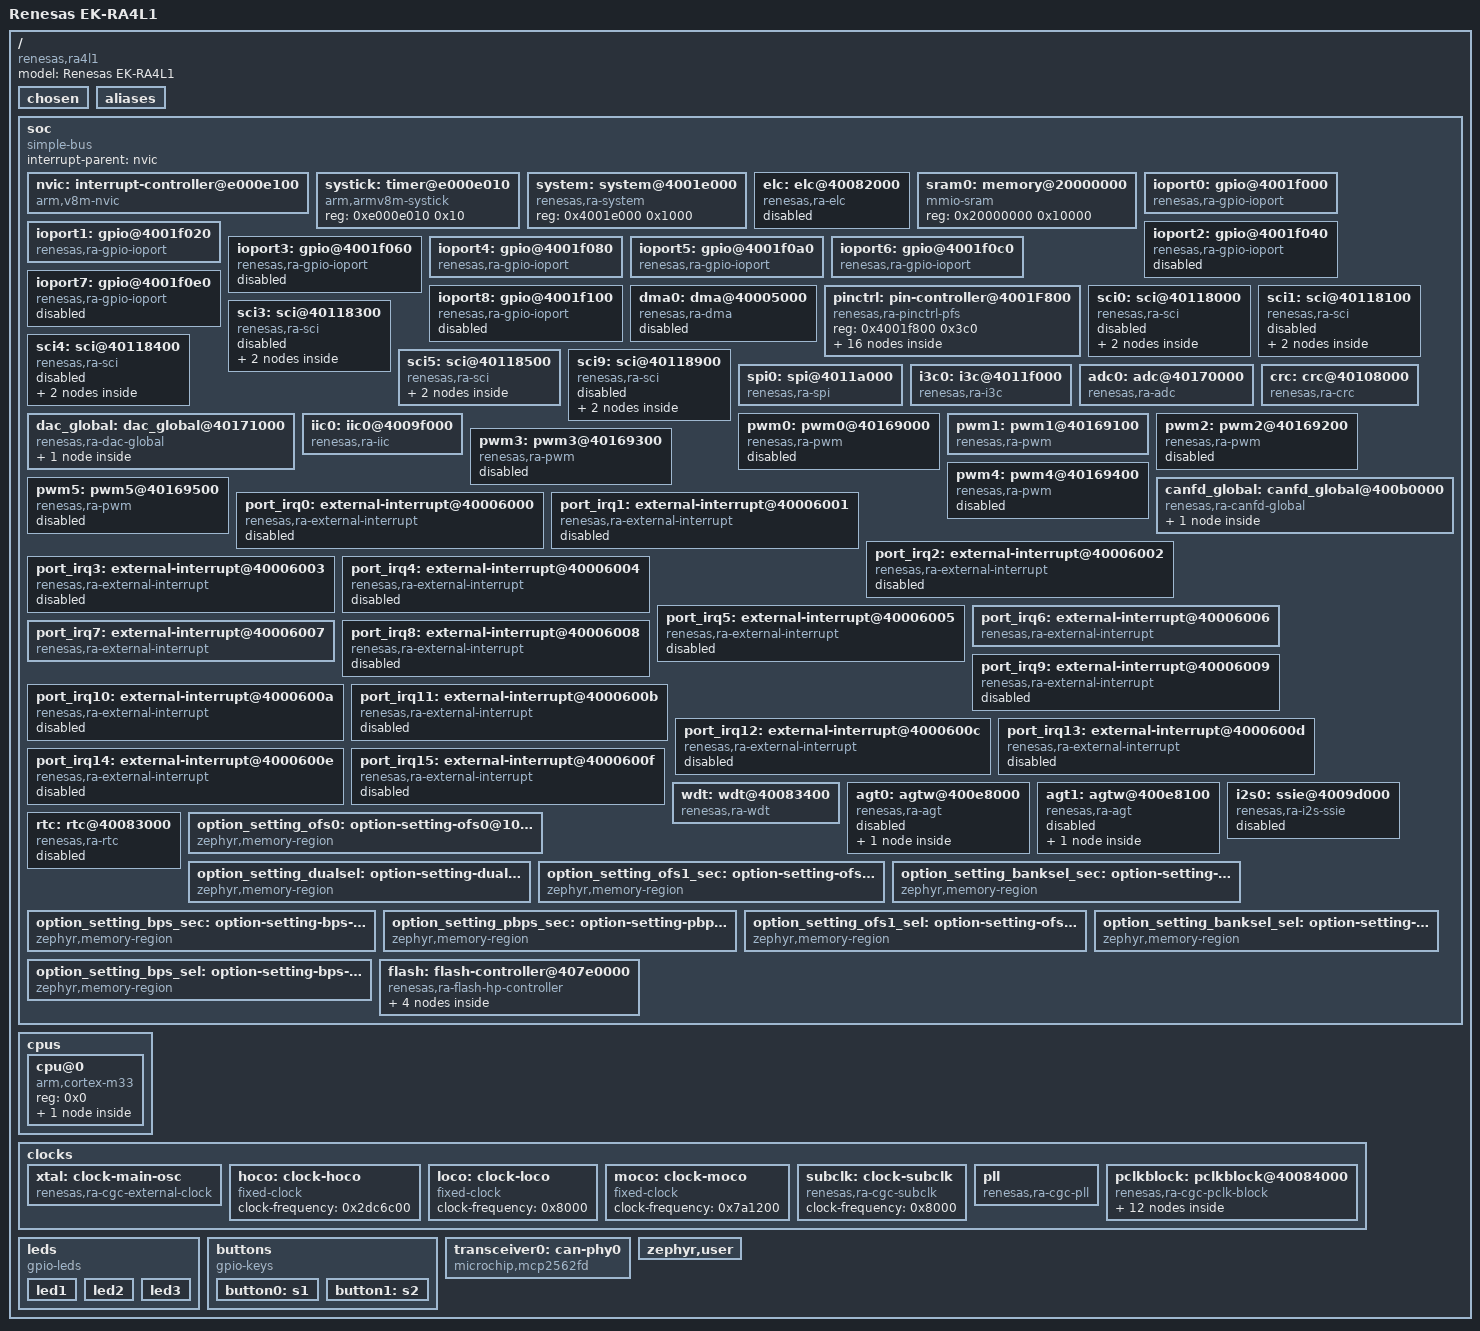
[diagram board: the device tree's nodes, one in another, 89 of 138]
/dts-v1/;

/* node '/' defined in zephyr/dts/common/skeleton.dtsi:9 */
/ {
	#address-cells = < 0x1 >;     /* in zephyr/dts/common/skeleton.dtsi:10 */
	#size-cells = < 0x1 >;        /* in zephyr/dts/common/skeleton.dtsi:11 */
	model = "Renesas EK-RA4L1";   /* in zephyr/boards/renesas/ek_ra4l1/ek_ra4l1.dts:15 */
	compatible = "renesas,ra4l1",
	             "renesas,ra";    /* in zephyr/boards/renesas/ek_ra4l1/ek_ra4l1.dts:16 */

	/* node '/chosen' defined in zephyr/dts/common/skeleton.dtsi:13 */
	chosen {
		zephyr,sram = &sram0;              /* in zephyr/boards/renesas/ek_ra4l1/ek_ra4l1.dts:19 */
		zephyr,flash-controller = &flash1; /* in zephyr/boards/renesas/ek_ra4l1/ek_ra4l1.dts:20 */
		zephyr,flash = &flash0;            /* in zephyr/boards/renesas/ek_ra4l1/ek_ra4l1.dts:21 */
		zephyr,console = &uart5;           /* in zephyr/boards/renesas/ek_ra4l1/ek_ra4l1.dts:22 */
		zephyr,shell-uart = &uart5;        /* in zephyr/boards/renesas/ek_ra4l1/ek_ra4l1.dts:23 */
		zephyr,canbus = &canfd0;           /* in zephyr/boards/renesas/ek_ra4l1/ek_ra4l1.dts:24 */
		zephyr,crc = &crc;                 /* in zephyr/boards/renesas/ek_ra4l1/ek_ra4l1.dts:25 */
	};

	/* node '/aliases' defined in zephyr/dts/common/skeleton.dtsi:15 */
	aliases {
		led0 = &led1;     /* in zephyr/boards/renesas/ek_ra4l1/ek_ra4l1.dts:64 */
		sw0 = &button0;   /* in zephyr/boards/renesas/ek_ra4l1/ek_ra4l1.dts:65 */
		sw1 = &button1;   /* in zephyr/boards/renesas/ek_ra4l1/ek_ra4l1.dts:66 */
		watchdog0 = &wdt; /* in zephyr/boards/renesas/ek_ra4l1/ek_ra4l1.dts:67 */
	};

	/* node '/soc' defined in zephyr/dts/arm/armv8-m.dtsi:6 */
	soc {
		#address-cells = < 0x1 >;     /* in zephyr/dts/arm/armv8-m.dtsi:7 */
		#size-cells = < 0x1 >;        /* in zephyr/dts/arm/armv8-m.dtsi:8 */
		compatible = "simple-bus";    /* in zephyr/dts/arm/armv8-m.dtsi:9 */
		ranges;                       /* in zephyr/dts/arm/armv8-m.dtsi:11 */
		interrupt-parent = < &nvic >; /* in zephyr/dts/arm/renesas/ra/ra4/r7fa4l1bx.dtsi:35 */

		/* node '/soc/interrupt-controller@e000e100' defined in zephyr/dts/arm/armv8-m.dtsi:13 */
		nvic: interrupt-controller@e000e100 {
			#address-cells = < 0x1 >;            /* in zephyr/dts/arm/armv8-m.dtsi:14 */
			compatible = "arm,v8m-nvic";         /* in zephyr/dts/arm/armv8-m.dtsi:15 */
			reg = < 0xe000e100 0xc00 >;          /* in zephyr/dts/arm/armv8-m.dtsi:16 */
			interrupt-controller;                /* in zephyr/dts/arm/armv8-m.dtsi:17 */
			#interrupt-cells = < 0x2 >;          /* in zephyr/dts/arm/armv8-m.dtsi:18 */
			arm,num-irq-priority-bits = < 0x4 >; /* in zephyr/dts/arm/renesas/ra/ra4/r7fa4l1bx.dtsi:839 */
			phandle = < 0x1 >;                   /* in zephyr/dts/arm/renesas/ra/ra4/r7fa4l1bx.dtsi:35 */
		};

		/* node '/soc/timer@e000e010' defined in zephyr/dts/arm/armv8-m.dtsi:21 */
		systick: timer@e000e010 {
			compatible = "arm,armv8m-systick"; /* in zephyr/dts/arm/armv8-m.dtsi:22 */
			reg = < 0xe000e010 0x10 >;         /* in zephyr/dts/arm/armv8-m.dtsi:23 */
		};

		/* node '/soc/system@4001e000' defined in zephyr/dts/arm/renesas/ra/ra4/r7fa4l1bx.dtsi:37 */
		system: system@4001e000 {
			compatible = "renesas,ra-system"; /* in zephyr/dts/arm/renesas/ra/ra4/r7fa4l1bx.dtsi:38 */
			reg = < 0x4001e000 0x1000 >;      /* in zephyr/dts/arm/renesas/ra/ra4/r7fa4l1bx.dtsi:39 */
			status = "okay";                  /* in zephyr/dts/arm/renesas/ra/ra4/r7fa4l1bx.dtsi:40 */
		};

		/* node '/soc/elc@40082000' defined in zephyr/dts/arm/renesas/ra/ra4/r7fa4l1bx.dtsi:43 */
		elc: elc@40082000 {
			compatible = "renesas,ra-elc"; /* in zephyr/dts/arm/renesas/ra/ra4/r7fa4l1bx.dtsi:44 */
			reg = < 0x40082000 0x70 >;     /* in zephyr/dts/arm/renesas/ra/ra4/r7fa4l1bx.dtsi:45 */
			#renesas-elc-cells = < 0x2 >;  /* in zephyr/dts/arm/renesas/ra/ra4/r7fa4l1bx.dtsi:46 */
			clocks = < &pclkb 0x2 0xe >;   /* in zephyr/dts/arm/renesas/ra/ra4/r7fa4l1bx.dtsi:47 */
			status = "disabled";           /* in zephyr/dts/arm/renesas/ra/ra4/r7fa4l1bx.dtsi:48 */
		};

		/* node '/soc/memory@20000000' defined in zephyr/dts/arm/renesas/ra/ra4/r7fa4l1bx.dtsi:51 */
		sram0: memory@20000000 {
			compatible = "mmio-sram";     /* in zephyr/dts/arm/renesas/ra/ra4/r7fa4l1bx.dtsi:52 */
			reg = < 0x20000000 0x10000 >; /* in zephyr/dts/arm/renesas/ra/ra4/r7fa4l1bx.dtsi:53 */
		};

		/* node '/soc/gpio@4001f000' defined in zephyr/dts/arm/renesas/ra/ra4/r7fa4l1bx.dtsi:56 */
		ioport0: gpio@4001f000 {
			compatible = "renesas,ra-gpio-ioport";                                               /* in zephyr/dts/arm/renesas/ra/ra4/r7fa4l1bx.dtsi:57 */
			reg = < 0x4001f000 0x20 >;                                                           /* in zephyr/dts/arm/renesas/ra/ra4/r7fa4l1bx.dtsi:58 */
			port = < 0x0 >;                                                                      /* in zephyr/dts/arm/renesas/ra/ra4/r7fa4l1bx.dtsi:59 */
			gpio-controller;                                                                     /* in zephyr/dts/arm/renesas/ra/ra4/r7fa4l1bx.dtsi:60 */
			#gpio-cells = < 0x2 >;                                                               /* in zephyr/dts/arm/renesas/ra/ra4/r7fa4l1bx.dtsi:61 */
			ngpios = < 0x10 >;                                                                   /* in zephyr/dts/arm/renesas/ra/ra4/r7fa4l1bx.dtsi:62 */
			port-irqs = < &port_irq6 &port_irq7 &port_irq8 &port_irq9 &port_irq10 &port_irq11 >; /* in zephyr/dts/arm/renesas/ra/ra4/r7fa4l1bx.dtsi:843 */
			port-irq-names = "port-irq6",
			                 "port-irq7",
			                 "port-irq8",
			                 "port-irq9",
			                 "port-irq10",
			                 "port-irq11";                                                       /* in zephyr/dts/arm/renesas/ra/ra4/r7fa4l1bx.dtsi:845 */
			port-irq6-pins = < 0x0 >;                                                            /* in zephyr/dts/arm/renesas/ra/ra4/r7fa4l1bx.dtsi:851 */
			port-irq7-pins = < 0x1 >;                                                            /* in zephyr/dts/arm/renesas/ra/ra4/r7fa4l1bx.dtsi:852 */
			port-irq8-pins = < 0x2 >;                                                            /* in zephyr/dts/arm/renesas/ra/ra4/r7fa4l1bx.dtsi:853 */
			port-irq9-pins = < 0x4 >;                                                            /* in zephyr/dts/arm/renesas/ra/ra4/r7fa4l1bx.dtsi:854 */
			port-irq10-pins = < 0xa >;                                                           /* in zephyr/dts/arm/renesas/ra/ra4/r7fa4l1bx.dtsi:855 */
			port-irq11-pins = < 0xb >;                                                           /* in zephyr/dts/arm/renesas/ra/ra4/r7fa4l1bx.dtsi:856 */
			status = "okay";                                                                     /* in zephyr/boards/renesas/ek_ra4l1/ek_ra4l1.dts:125 */
			phandle = < 0x26 >;                                                                  /* in zephyr/boards/renesas/ek_ra4l1/ek_ra4l1.dts:51 */
		};

		/* node '/soc/gpio@4001f020' defined in zephyr/dts/arm/renesas/ra/ra4/r7fa4l1bx.dtsi:66 */
		ioport1: gpio@4001f020 {
			compatible = "renesas,ra-gpio-ioport";                                  /* in zephyr/dts/arm/renesas/ra/ra4/r7fa4l1bx.dtsi:67 */
			reg = < 0x4001f020 0x20 >;                                              /* in zephyr/dts/arm/renesas/ra/ra4/r7fa4l1bx.dtsi:68 */
			port = < 0x1 >;                                                         /* in zephyr/dts/arm/renesas/ra/ra4/r7fa4l1bx.dtsi:69 */
			gpio-controller;                                                        /* in zephyr/dts/arm/renesas/ra/ra4/r7fa4l1bx.dtsi:70 */
			#gpio-cells = < 0x2 >;                                                  /* in zephyr/dts/arm/renesas/ra/ra4/r7fa4l1bx.dtsi:71 */
			ngpios = < 0x10 >;                                                      /* in zephyr/dts/arm/renesas/ra/ra4/r7fa4l1bx.dtsi:72 */
			port-irqs = < &port_irq0 &port_irq1 &port_irq2 &port_irq3 &port_irq4 >; /* in zephyr/dts/arm/renesas/ra/ra4/r7fa4l1bx.dtsi:860 */
			port-irq-names = "port-irq0",
			                 "port-irq1",
			                 "port-irq2",
			                 "port-irq3",
			                 "port-irq4";                                           /* in zephyr/dts/arm/renesas/ra/ra4/r7fa4l1bx.dtsi:862 */
			port-irq0-pins = < 0x5 >;                                               /* in zephyr/dts/arm/renesas/ra/ra4/r7fa4l1bx.dtsi:867 */
			port-irq1-pins = < 0x1 0x4 >;                                           /* in zephyr/dts/arm/renesas/ra/ra4/r7fa4l1bx.dtsi:868 */
			port-irq2-pins = < 0x0 >;                                               /* in zephyr/dts/arm/renesas/ra/ra4/r7fa4l1bx.dtsi:869 */
			port-irq3-pins = < 0xa >;                                               /* in zephyr/dts/arm/renesas/ra/ra4/r7fa4l1bx.dtsi:870 */
			port-irq4-pins = < 0xb >;                                               /* in zephyr/dts/arm/renesas/ra/ra4/r7fa4l1bx.dtsi:871 */
			status = "okay";                                                        /* in zephyr/boards/renesas/ek_ra4l1/ek_ra4l1.dts:129 */
			phandle = < 0x27 >;                                                     /* in zephyr/boards/renesas/ek_ra4l1/ek_ra4l1.dts:72 */
		};

		/* node '/soc/gpio@4001f040' defined in zephyr/dts/arm/renesas/ra/ra4/r7fa4l1bx.dtsi:76 */
		ioport2: gpio@4001f040 {
			compatible = "renesas,ra-gpio-ioport";                                   /* in zephyr/dts/arm/renesas/ra/ra4/r7fa4l1bx.dtsi:77 */
			reg = < 0x4001f040 0x20 >;                                               /* in zephyr/dts/arm/renesas/ra/ra4/r7fa4l1bx.dtsi:78 */
			port = < 0x2 >;                                                          /* in zephyr/dts/arm/renesas/ra/ra4/r7fa4l1bx.dtsi:79 */
			gpio-controller;                                                         /* in zephyr/dts/arm/renesas/ra/ra4/r7fa4l1bx.dtsi:80 */
			#gpio-cells = < 0x2 >;                                                   /* in zephyr/dts/arm/renesas/ra/ra4/r7fa4l1bx.dtsi:81 */
			ngpios = < 0x10 >;                                                       /* in zephyr/dts/arm/renesas/ra/ra4/r7fa4l1bx.dtsi:82 */
			status = "disabled";                                                     /* in zephyr/dts/arm/renesas/ra/ra4/r7fa4l1bx.dtsi:83 */
			port-irqs = < &port_irq0 &port_irq1 &port_irq2 &port_irq3 &port_irq12 >; /* in zephyr/dts/arm/renesas/ra/ra4/r7fa4l1bx.dtsi:875 */
			port-irq-names = "port-irq0",
			                 "port-irq1",
			                 "port-irq2",
			                 "port-irq3",
			                 "port-irq12";                                           /* in zephyr/dts/arm/renesas/ra/ra4/r7fa4l1bx.dtsi:877 */
			port-irq0-pins = < 0x6 >;                                                /* in zephyr/dts/arm/renesas/ra/ra4/r7fa4l1bx.dtsi:882 */
			port-irq1-pins = < 0x5 >;                                                /* in zephyr/dts/arm/renesas/ra/ra4/r7fa4l1bx.dtsi:883 */
			port-irq2-pins = < 0xd >;                                                /* in zephyr/dts/arm/renesas/ra/ra4/r7fa4l1bx.dtsi:884 */
			port-irq3-pins = < 0xc >;                                                /* in zephyr/dts/arm/renesas/ra/ra4/r7fa4l1bx.dtsi:885 */
			port-irq12-pins = < 0x8 >;                                               /* in zephyr/dts/arm/renesas/ra/ra4/r7fa4l1bx.dtsi:886 */
		};

		/* node '/soc/gpio@4001f060' defined in zephyr/dts/arm/renesas/ra/ra4/r7fa4l1bx.dtsi:86 */
		ioport3: gpio@4001f060 {
			compatible = "renesas,ra-gpio-ioport";                       /* in zephyr/dts/arm/renesas/ra/ra4/r7fa4l1bx.dtsi:87 */
			reg = < 0x4001f060 0x20 >;                                   /* in zephyr/dts/arm/renesas/ra/ra4/r7fa4l1bx.dtsi:88 */
			port = < 0x3 >;                                              /* in zephyr/dts/arm/renesas/ra/ra4/r7fa4l1bx.dtsi:89 */
			gpio-controller;                                             /* in zephyr/dts/arm/renesas/ra/ra4/r7fa4l1bx.dtsi:90 */
			#gpio-cells = < 0x2 >;                                       /* in zephyr/dts/arm/renesas/ra/ra4/r7fa4l1bx.dtsi:91 */
			ngpios = < 0x10 >;                                           /* in zephyr/dts/arm/renesas/ra/ra4/r7fa4l1bx.dtsi:92 */
			status = "disabled";                                         /* in zephyr/dts/arm/renesas/ra/ra4/r7fa4l1bx.dtsi:93 */
			port-irqs = < &port_irq5 &port_irq6 &port_irq8 &port_irq9 >; /* in zephyr/dts/arm/renesas/ra/ra4/r7fa4l1bx.dtsi:890 */
			port-irq-names = "port-irq5",
			                 "port-irq6",
			                 "port-irq8",
			                 "port-irq9";                                /* in zephyr/dts/arm/renesas/ra/ra4/r7fa4l1bx.dtsi:892 */
			port-irq5-pins = < 0x2 >;                                    /* in zephyr/dts/arm/renesas/ra/ra4/r7fa4l1bx.dtsi:896 */
			port-irq6-pins = < 0x1 >;                                    /* in zephyr/dts/arm/renesas/ra/ra4/r7fa4l1bx.dtsi:897 */
			port-irq8-pins = < 0x5 >;                                    /* in zephyr/dts/arm/renesas/ra/ra4/r7fa4l1bx.dtsi:898 */
			port-irq9-pins = < 0x4 >;                                    /* in zephyr/dts/arm/renesas/ra/ra4/r7fa4l1bx.dtsi:899 */
		};

		/* node '/soc/gpio@4001f080' defined in zephyr/dts/arm/renesas/ra/ra4/r7fa4l1bx.dtsi:96 */
		ioport4: gpio@4001f080 {
			compatible = "renesas,ra-gpio-ioport";                                                                 /* in zephyr/dts/arm/renesas/ra/ra4/r7fa4l1bx.dtsi:97 */
			reg = < 0x4001f080 0x20 >;                                                                             /* in zephyr/dts/arm/renesas/ra/ra4/r7fa4l1bx.dtsi:98 */
			port = < 0x4 >;                                                                                        /* in zephyr/dts/arm/renesas/ra/ra4/r7fa4l1bx.dtsi:99 */
			gpio-controller;                                                                                       /* in zephyr/dts/arm/renesas/ra/ra4/r7fa4l1bx.dtsi:100 */
			#gpio-cells = < 0x2 >;                                                                                 /* in zephyr/dts/arm/renesas/ra/ra4/r7fa4l1bx.dtsi:101 */
			ngpios = < 0x10 >;                                                                                     /* in zephyr/dts/arm/renesas/ra/ra4/r7fa4l1bx.dtsi:102 */
			port-irqs = < &port_irq0 &port_irq4 &port_irq5 &port_irq6 &port_irq7 &port_irq8 &port_irq9 &port_irq14
			              &port_irq15 >;                                                                           /* in zephyr/dts/arm/renesas/ra/ra4/r7fa4l1bx.dtsi:903 */
			port-irq-names = "port-irq0",
			                 "port-irq4",
			                 "port-irq5",
			                 "port-irq6",
			                 "port-irq7",
			                 "port-irq8",
			                 "port-irq9",
			                 "port-irq14",
			                 "port-irq15";                                                                         /* in zephyr/dts/arm/renesas/ra/ra4/r7fa4l1bx.dtsi:906 */
			port-irq0-pins = < 0x0 >;                                                                              /* in zephyr/dts/arm/renesas/ra/ra4/r7fa4l1bx.dtsi:915 */
			port-irq4-pins = < 0x2 0xb >;                                                                          /* in zephyr/dts/arm/renesas/ra/ra4/r7fa4l1bx.dtsi:916 */
			port-irq5-pins = < 0x1 0xa >;                                                                          /* in zephyr/dts/arm/renesas/ra/ra4/r7fa4l1bx.dtsi:917 */
			port-irq6-pins = < 0x9 >;                                                                              /* in zephyr/dts/arm/renesas/ra/ra4/r7fa4l1bx.dtsi:918 */
			port-irq7-pins = < 0x8 >;                                                                              /* in zephyr/dts/arm/renesas/ra/ra4/r7fa4l1bx.dtsi:919 */
			port-irq8-pins = < 0xf >;                                                                              /* in zephyr/dts/arm/renesas/ra/ra4/r7fa4l1bx.dtsi:920 */
			port-irq9-pins = < 0xe >;                                                                              /* in zephyr/dts/arm/renesas/ra/ra4/r7fa4l1bx.dtsi:921 */
			port-irq14-pins = < 0x3 >;                                                                             /* in zephyr/dts/arm/renesas/ra/ra4/r7fa4l1bx.dtsi:922 */
			port-irq15-pins = < 0x4 >;                                                                             /* in zephyr/dts/arm/renesas/ra/ra4/r7fa4l1bx.dtsi:923 */
			status = "okay";                                                                                       /* in zephyr/boards/renesas/ek_ra4l1/ek_ra4l1.dts:133 */
		};

		/* node '/soc/gpio@4001f0a0' defined in zephyr/dts/arm/renesas/ra/ra4/r7fa4l1bx.dtsi:106 */
		ioport5: gpio@4001f0a0 {
			compatible = "renesas,ra-gpio-ioport";                           /* in zephyr/dts/arm/renesas/ra/ra4/r7fa4l1bx.dtsi:107 */
			reg = < 0x4001f0a0 0x20 >;                                       /* in zephyr/dts/arm/renesas/ra/ra4/r7fa4l1bx.dtsi:108 */
			port = < 0x5 >;                                                  /* in zephyr/dts/arm/renesas/ra/ra4/r7fa4l1bx.dtsi:109 */
			gpio-controller;                                                 /* in zephyr/dts/arm/renesas/ra/ra4/r7fa4l1bx.dtsi:110 */
			#gpio-cells = < 0x2 >;                                           /* in zephyr/dts/arm/renesas/ra/ra4/r7fa4l1bx.dtsi:111 */
			ngpios = < 0x10 >;                                               /* in zephyr/dts/arm/renesas/ra/ra4/r7fa4l1bx.dtsi:112 */
			port-irqs = < &port_irq11 &port_irq12 &port_irq13 &port_irq14 >; /* in zephyr/dts/arm/renesas/ra/ra4/r7fa4l1bx.dtsi:927 */
			port-irq-names = "port-irq11",
			                 "port-irq12",
			                 "port-irq13",
			                 "port-irq14";                                   /* in zephyr/dts/arm/renesas/ra/ra4/r7fa4l1bx.dtsi:929 */
			port-irq11-pins = < 0x1 >;                                       /* in zephyr/dts/arm/renesas/ra/ra4/r7fa4l1bx.dtsi:933 */
			port-irq12-pins = < 0x2 >;                                       /* in zephyr/dts/arm/renesas/ra/ra4/r7fa4l1bx.dtsi:934 */
			port-irq13-pins = < 0x6 >;                                       /* in zephyr/dts/arm/renesas/ra/ra4/r7fa4l1bx.dtsi:935 */
			port-irq14-pins = < 0x5 >;                                       /* in zephyr/dts/arm/renesas/ra/ra4/r7fa4l1bx.dtsi:936 */
			status = "okay";                                                 /* in zephyr/boards/renesas/ek_ra4l1/ek_ra4l1.dts:137 */
			phandle = < 0x28 >;                                              /* in zephyr/boards/renesas/ek_ra4l1/ek_ra4l1.dts:78 */
		};

		/* node '/soc/gpio@4001f0c0' defined in zephyr/dts/arm/renesas/ra/ra4/r7fa4l1bx.dtsi:116 */
		ioport6: gpio@4001f0c0 {
			compatible = "renesas,ra-gpio-ioport"; /* in zephyr/dts/arm/renesas/ra/ra4/r7fa4l1bx.dtsi:117 */
			reg = < 0x4001f0c0 0x20 >;             /* in zephyr/dts/arm/renesas/ra/ra4/r7fa4l1bx.dtsi:118 */
			port = < 0x6 >;                        /* in zephyr/dts/arm/renesas/ra/ra4/r7fa4l1bx.dtsi:119 */
			gpio-controller;                       /* in zephyr/dts/arm/renesas/ra/ra4/r7fa4l1bx.dtsi:120 */
			#gpio-cells = < 0x2 >;                 /* in zephyr/dts/arm/renesas/ra/ra4/r7fa4l1bx.dtsi:121 */
			ngpios = < 0x10 >;                     /* in zephyr/dts/arm/renesas/ra/ra4/r7fa4l1bx.dtsi:122 */
			status = "okay";                       /* in zephyr/boards/renesas/ek_ra4l1/ek_ra4l1.dts:141 */
			phandle = < 0x25 >;                    /* in zephyr/boards/renesas/ek_ra4l1/ek_ra4l1.dts:32 */
		};

		/* node '/soc/gpio@4001f0e0' defined in zephyr/dts/arm/renesas/ra/ra4/r7fa4l1bx.dtsi:126 */
		ioport7: gpio@4001f0e0 {
			compatible = "renesas,ra-gpio-ioport"; /* in zephyr/dts/arm/renesas/ra/ra4/r7fa4l1bx.dtsi:127 */
			reg = < 0x4001f0e0 0x20 >;             /* in zephyr/dts/arm/renesas/ra/ra4/r7fa4l1bx.dtsi:128 */
			port = < 0x7 >;                        /* in zephyr/dts/arm/renesas/ra/ra4/r7fa4l1bx.dtsi:129 */
			gpio-controller;                       /* in zephyr/dts/arm/renesas/ra/ra4/r7fa4l1bx.dtsi:130 */
			#gpio-cells = < 0x2 >;                 /* in zephyr/dts/arm/renesas/ra/ra4/r7fa4l1bx.dtsi:131 */
			ngpios = < 0x10 >;                     /* in zephyr/dts/arm/renesas/ra/ra4/r7fa4l1bx.dtsi:132 */
			status = "disabled";                   /* in zephyr/dts/arm/renesas/ra/ra4/r7fa4l1bx.dtsi:133 */
			port-irqs = < &port_irq11 >;           /* in zephyr/dts/arm/renesas/ra/ra4/r7fa4l1bx.dtsi:940 */
			port-irq-names = "port-irq11";         /* in zephyr/dts/arm/renesas/ra/ra4/r7fa4l1bx.dtsi:941 */
			port-irq11-pins = < 0x8 >;             /* in zephyr/dts/arm/renesas/ra/ra4/r7fa4l1bx.dtsi:942 */
		};

		/* node '/soc/gpio@4001f100' defined in zephyr/dts/arm/renesas/ra/ra4/r7fa4l1bx.dtsi:136 */
		ioport8: gpio@4001f100 {
			compatible = "renesas,ra-gpio-ioport"; /* in zephyr/dts/arm/renesas/ra/ra4/r7fa4l1bx.dtsi:137 */
			reg = < 0x4001f100 0x20 >;             /* in zephyr/dts/arm/renesas/ra/ra4/r7fa4l1bx.dtsi:138 */
			port = < 0x8 >;                        /* in zephyr/dts/arm/renesas/ra/ra4/r7fa4l1bx.dtsi:139 */
			gpio-controller;                       /* in zephyr/dts/arm/renesas/ra/ra4/r7fa4l1bx.dtsi:140 */
			#gpio-cells = < 0x2 >;                 /* in zephyr/dts/arm/renesas/ra/ra4/r7fa4l1bx.dtsi:141 */
			ngpios = < 0x10 >;                     /* in zephyr/dts/arm/renesas/ra/ra4/r7fa4l1bx.dtsi:142 */
			status = "disabled";                   /* in zephyr/dts/arm/renesas/ra/ra4/r7fa4l1bx.dtsi:143 */
		};

		/* node '/soc/dma@40005000' defined in zephyr/dts/arm/renesas/ra/ra4/r7fa4l1bx.dtsi:146 */
		dma0: dma@40005000 {
			compatible = "renesas,ra-dma"; /* in zephyr/dts/arm/renesas/ra/ra4/r7fa4l1bx.dtsi:147 */
			reg = < 0x40005000 0x200 >,
			      < 0x40005200 0xa0 >;     /* in zephyr/dts/arm/renesas/ra/ra4/r7fa4l1bx.dtsi:148 */
			reg-names = "channel",
			            "common";          /* in zephyr/dts/arm/renesas/ra/ra4/r7fa4l1bx.dtsi:149 */
			clocks = < &iclk 0x0 0x16 >;   /* in zephyr/dts/arm/renesas/ra/ra4/r7fa4l1bx.dtsi:150 */
			dma-channels = < 0x8 >;        /* in zephyr/dts/arm/renesas/ra/ra4/r7fa4l1bx.dtsi:151 */
			#dma-cells = < 0x2 >;          /* in zephyr/dts/arm/renesas/ra/ra4/r7fa4l1bx.dtsi:152 */
			status = "disabled";           /* in zephyr/dts/arm/renesas/ra/ra4/r7fa4l1bx.dtsi:153 */
		};

		/* node '/soc/pin-controller@4001F800' defined in zephyr/dts/arm/renesas/ra/ra4/r7fa4l1bx.dtsi:156 */
		pinctrl: pin-controller@4001F800 {
			compatible = "renesas,ra-pinctrl-pfs"; /* in zephyr/dts/arm/renesas/ra/ra4/r7fa4l1bx.dtsi:157 */
			reg = < 0x4001f800 0x3c0 >;            /* in zephyr/dts/arm/renesas/ra/ra4/r7fa4l1bx.dtsi:158 */
			status = "okay";                       /* in zephyr/dts/arm/renesas/ra/ra4/r7fa4l1bx.dtsi:159 */

			/* node '/soc/pin-controller@4001F800/sci5_default' defined in zephyr/boards/renesas/ek_ra4l1/ek_ra4l1-pinctrl.dtsi:7 */
			sci5_default: sci5_default {
				phandle = < 0x15 >; /* in zephyr/boards/renesas/ek_ra4l1/ek_ra4l1.dts:114 */

				/* node '/soc/pin-controller@4001F800/sci5_default/group1' defined in zephyr/boards/renesas/ek_ra4l1/ek_ra4l1-pinctrl.dtsi:8 */
				group1 {
					psels = < 0x2565 >,
					        < 0x2575 >; /* in zephyr/boards/renesas/ek_ra4l1/ek_ra4l1-pinctrl.dtsi:10 */
				};
			};

			/* node '/soc/pin-controller@4001F800/spi0_default' defined in zephyr/boards/renesas/ek_ra4l1/ek_ra4l1-pinctrl.dtsi:15 */
			spi0_default: spi0_default {
				phandle = < 0x16 >; /* in zephyr/boards/renesas/ek_ra4l1/ek_ra4l1.dts:145 */

				/* node '/soc/pin-controller@4001F800/spi0_default/group1' defined in zephyr/boards/renesas/ek_ra4l1/ek_ra4l1-pinctrl.dtsi:16 */
				group1 {
					psels = < 0x26a1 >,
					        < 0x2691 >,
					        < 0x26b1 >,
					        < 0x26c1 >; /* in zephyr/boards/renesas/ek_ra4l1/ek_ra4l1-pinctrl.dtsi:18 */
				};
			};

			/* node '/soc/pin-controller@4001F800/i3c0_default' defined in zephyr/boards/renesas/ek_ra4l1/ek_ra4l1-pinctrl.dtsi:25 */
			i3c0_default: i3c0_default {
				phandle = < 0x18 >; /* in zephyr/boards/renesas/ek_ra4l1/ek_ra4l1.dts:153 */

				/* node '/soc/pin-controller@4001F800/i3c0_default/group1' defined in zephyr/boards/renesas/ek_ra4l1/ek_ra4l1-pinctrl.dtsi:26 */
				group1 {
					psels = < 0x2704 >,
					        < 0x2714 >; /* in zephyr/boards/renesas/ek_ra4l1/ek_ra4l1-pinctrl.dtsi:28 */
				};
			};

			/* node '/soc/pin-controller@4001F800/adc0_default' defined in zephyr/boards/renesas/ek_ra4l1/ek_ra4l1-pinctrl.dtsi:33 */
			adc0_default: adc0_default {
				phandle = < 0x19 >; /* in zephyr/boards/renesas/ek_ra4l1/ek_ra4l1.dts:162 */

				/* node '/soc/pin-controller@4001F800/adc0_default/group1' defined in zephyr/boards/renesas/ek_ra4l1/ek_ra4l1-pinctrl.dtsi:34 */
				group1 {
					psels = < 0x2030 >;    /* in zephyr/boards/renesas/ek_ra4l1/ek_ra4l1-pinctrl.dtsi:36 */
					renesas,analog-enable; /* in zephyr/boards/renesas/ek_ra4l1/ek_ra4l1-pinctrl.dtsi:37 */
				};
			};

			/* node '/soc/pin-controller@4001F800/dac0_default' defined in zephyr/boards/renesas/ek_ra4l1/ek_ra4l1-pinctrl.dtsi:41 */
			dac0_default: dac0_default {
				phandle = < 0x1a >; /* in zephyr/boards/renesas/ek_ra4l1/ek_ra4l1.dts:167 */

				/* node '/soc/pin-controller@4001F800/dac0_default/group1' defined in zephyr/boards/renesas/ek_ra4l1/ek_ra4l1-pinctrl.dtsi:42 */
				group1 {
					psels = < 0x2040 >;    /* in zephyr/boards/renesas/ek_ra4l1/ek_ra4l1-pinctrl.dtsi:44 */
					renesas,analog-enable; /* in zephyr/boards/renesas/ek_ra4l1/ek_ra4l1-pinctrl.dtsi:45 */
				};
			};

			/* node '/soc/pin-controller@4001F800/pwm1_default' defined in zephyr/boards/renesas/ek_ra4l1/ek_ra4l1-pinctrl.dtsi:49 */
			pwm1_default: pwm1_default {
				phandle = < 0x1d >; /* in zephyr/boards/renesas/ek_ra4l1/ek_ra4l1.dts:183 */

				/* node '/soc/pin-controller@4001F800/pwm1_default/group1' defined in zephyr/boards/renesas/ek_ra4l1/ek_ra4l1-pinctrl.dtsi:50 */
				group1 {
					psels = < 0x2354 >,
					        < 0x2364 >; /* in zephyr/boards/renesas/ek_ra4l1/ek_ra4l1-pinctrl.dtsi:52 */
				};
			};

			/* node '/soc/pin-controller@4001F800/iic0_default' defined in zephyr/boards/renesas/ek_ra4l1/ek_ra4l1-pinctrl.dtsi:57 */
			iic0_default: iic0_default {
				phandle = < 0x1b >; /* in zephyr/boards/renesas/ek_ra4l1/ek_ra4l1.dts:191 */

				/* node '/soc/pin-controller@4001F800/iic0_default/group1' defined in zephyr/boards/renesas/ek_ra4l1/ek_ra4l1-pinctrl.dtsi:58 */
				group1 {
					psels = < 0x2711 >,
					        < 0x2701 >;        /* in zephyr/boards/renesas/ek_ra4l1/ek_ra4l1-pinctrl.dtsi:60 */
					drive-strength = "medium"; /* in zephyr/boards/renesas/ek_ra4l1/ek_ra4l1-pinctrl.dtsi:62 */
				};
			};

			/* node '/soc/pin-controller@4001F800/canfd0_default' defined in zephyr/boards/renesas/ek_ra4l1/ek_ra4l1-pinctrl.dtsi:66 */
			canfd0_default: canfd0_default {
				phandle = < 0x1f >; /* in zephyr/boards/renesas/ek_ra4l1/ek_ra4l1.dts:205 */

				/* node '/soc/pin-controller@4001F800/canfd0_default/group1' defined in zephyr/boards/renesas/ek_ra4l1/ek_ra4l1-pinctrl.dtsi:67 */
				group1 {
					psels = < 0x3031 >,
					        < 0x3021 >;      /* in zephyr/boards/renesas/ek_ra4l1/ek_ra4l1-pinctrl.dtsi:69 */
					drive-strength = "high"; /* in zephyr/boards/renesas/ek_ra4l1/ek_ra4l1-pinctrl.dtsi:71 */
				};
			};
		};

		/* node '/soc/sci@40118000' defined in zephyr/dts/arm/renesas/ra/ra4/r7fa4l1bx.dtsi:162 */
		sci0: sci@40118000 {
			compatible = "renesas,ra-sci"; /* in zephyr/dts/arm/renesas/ra/ra4/r7fa4l1bx.dtsi:163 */
			reg = < 0x40118000 0x100 >;    /* in zephyr/dts/arm/renesas/ra/ra4/r7fa4l1bx.dtsi:164 */
			clocks = < &pclka 0x1 0x1f >;  /* in zephyr/dts/arm/renesas/ra/ra4/r7fa4l1bx.dtsi:165 */
			status = "disabled";           /* in zephyr/dts/arm/renesas/ra/ra4/r7fa4l1bx.dtsi:166 */

			/* node '/soc/sci@40118000/uart' defined in zephyr/dts/arm/renesas/ra/ra4/r7fa4l1bx.dtsi:168 */
			uart {
				compatible = "renesas,ra-sci-uart"; /* in zephyr/dts/arm/renesas/ra/ra4/r7fa4l1bx.dtsi:169 */
				channel = < 0x0 >;                  /* in zephyr/dts/arm/renesas/ra/ra4/r7fa4l1bx.dtsi:170 */
				status = "disabled";                /* in zephyr/dts/arm/renesas/ra/ra4/r7fa4l1bx.dtsi:171 */
			};

			/* node '/soc/sci@40118000/i2c' defined in zephyr/dts/arm/renesas/ra/ra4/r7fa4l1bx.dtsi:174 */
			i2c {
				compatible = "renesas,ra-i2c-sci"; /* in zephyr/dts/arm/renesas/ra/ra4/r7fa4l1bx.dtsi:175 */
				#address-cells = < 0x1 >;          /* in zephyr/dts/arm/renesas/ra/ra4/r7fa4l1bx.dtsi:176 */
				#size-cells = < 0x0 >;             /* in zephyr/dts/arm/renesas/ra/ra4/r7fa4l1bx.dtsi:177 */
				channel = < 0x0 >;                 /* in zephyr/dts/arm/renesas/ra/ra4/r7fa4l1bx.dtsi:178 */
				status = "disabled";               /* in zephyr/dts/arm/renesas/ra/ra4/r7fa4l1bx.dtsi:179 */
			};
		};

		/* node '/soc/sci@40118100' defined in zephyr/dts/arm/renesas/ra/ra4/r7fa4l1bx.dtsi:183 */
		sci1: sci@40118100 {
			compatible = "renesas,ra-sci"; /* in zephyr/dts/arm/renesas/ra/ra4/r7fa4l1bx.dtsi:184 */
			reg = < 0x40118100 0x100 >;    /* in zephyr/dts/arm/renesas/ra/ra4/r7fa4l1bx.dtsi:185 */
			clocks = < &pclka 0x1 0x1e >;  /* in zephyr/dts/arm/renesas/ra/ra4/r7fa4l1bx.dtsi:186 */
			status = "disabled";           /* in zephyr/dts/arm/renesas/ra/ra4/r7fa4l1bx.dtsi:187 */

			/* node '/soc/sci@40118100/uart' defined in zephyr/dts/arm/renesas/ra/ra4/r7fa4l1bx.dtsi:189 */
			uart {
				compatible = "renesas,ra-sci-uart"; /* in zephyr/dts/arm/renesas/ra/ra4/r7fa4l1bx.dtsi:190 */
				channel = < 0x1 >;                  /* in zephyr/dts/arm/renesas/ra/ra4/r7fa4l1bx.dtsi:191 */
				status = "disabled";                /* in zephyr/dts/arm/renesas/ra/ra4/r7fa4l1bx.dtsi:192 */
			};

			/* node '/soc/sci@40118100/i2c' defined in zephyr/dts/arm/renesas/ra/ra4/r7fa4l1bx.dtsi:195 */
			i2c {
				compatible = "renesas,ra-i2c-sci"; /* in zephyr/dts/arm/renesas/ra/ra4/r7fa4l1bx.dtsi:196 */
				#address-cells = < 0x1 >;          /* in zephyr/dts/arm/renesas/ra/ra4/r7fa4l1bx.dtsi:197 */
				#size-cells = < 0x0 >;             /* in zephyr/dts/arm/renesas/ra/ra4/r7fa4l1bx.dtsi:198 */
				channel = < 0x1 >;                 /* in zephyr/dts/arm/renesas/ra/ra4/r7fa4l1bx.dtsi:199 */
				status = "disabled";               /* in zephyr/dts/arm/renesas/ra/ra4/r7fa4l1bx.dtsi:200 */
			};
		};

		/* node '/soc/sci@40118300' defined in zephyr/dts/arm/renesas/ra/ra4/r7fa4l1bx.dtsi:204 */
		sci3: sci@40118300 {
			compatible = "renesas,ra-sci"; /* in zephyr/dts/arm/renesas/ra/ra4/r7fa4l1bx.dtsi:205 */
			reg = < 0x40118300 0x100 >;    /* in zephyr/dts/arm/renesas/ra/ra4/r7fa4l1bx.dtsi:206 */
			clocks = < &pclka 0x1 0x26 >;  /* in zephyr/dts/arm/renesas/ra/ra4/r7fa4l1bx.dtsi:207 */
			status = "disabled";           /* in zephyr/dts/arm/renesas/ra/ra4/r7fa4l1bx.dtsi:208 */

			/* node '/soc/sci@40118300/uart' defined in zephyr/dts/arm/renesas/ra/ra4/r7fa4l1bx.dtsi:210 */
			uart {
				compatible = "renesas,ra-sci-uart"; /* in zephyr/dts/arm/renesas/ra/ra4/r7fa4l1bx.dtsi:211 */
				channel = < 0x3 >;                  /* in zephyr/dts/arm/renesas/ra/ra4/r7fa4l1bx.dtsi:212 */
				status = "disabled";                /* in zephyr/dts/arm/renesas/ra/ra4/r7fa4l1bx.dtsi:213 */
			};

			/* node '/soc/sci@40118300/i2c' defined in zephyr/dts/arm/renesas/ra/ra4/r7fa4l1bx.dtsi:216 */
			i2c {
				compatible = "renesas,ra-i2c-sci"; /* in zephyr/dts/arm/renesas/ra/ra4/r7fa4l1bx.dtsi:217 */
				#address-cells = < 0x1 >;          /* in zephyr/dts/arm/renesas/ra/ra4/r7fa4l1bx.dtsi:218 */
				#size-cells = < 0x0 >;             /* in zephyr/dts/arm/renesas/ra/ra4/r7fa4l1bx.dtsi:219 */
				channel = < 0x3 >;                 /* in zephyr/dts/arm/renesas/ra/ra4/r7fa4l1bx.dtsi:220 */
				status = "disabled";               /* in zephyr/dts/arm/renesas/ra/ra4/r7fa4l1bx.dtsi:221 */
			};
		};

		/* node '/soc/sci@40118400' defined in zephyr/dts/arm/renesas/ra/ra4/r7fa4l1bx.dtsi:225 */
		sci4: sci@40118400 {
			compatible = "renesas,ra-sci"; /* in zephyr/dts/arm/renesas/ra/ra4/r7fa4l1bx.dtsi:226 */
			reg = < 0x40118400 0x100 >;    /* in zephyr/dts/arm/renesas/ra/ra4/r7fa4l1bx.dtsi:227 */
			clocks = < &pclka 0x1 0x1b >;  /* in zephyr/dts/arm/renesas/ra/ra4/r7fa4l1bx.dtsi:228 */
			status = "disabled";           /* in zephyr/dts/arm/renesas/ra/ra4/r7fa4l1bx.dtsi:229 */

			/* node '/soc/sci@40118400/uart' defined in zephyr/dts/arm/renesas/ra/ra4/r7fa4l1bx.dtsi:231 */
			uart {
				compatible = "renesas,ra-sci-uart"; /* in zephyr/dts/arm/renesas/ra/ra4/r7fa4l1bx.dtsi:232 */
				channel = < 0x4 >;                  /* in zephyr/dts/arm/renesas/ra/ra4/r7fa4l1bx.dtsi:233 */
				status = "disabled";                /* in zephyr/dts/arm/renesas/ra/ra4/r7fa4l1bx.dtsi:234 */
			};

			/* node '/soc/sci@40118400/i2c' defined in zephyr/dts/arm/renesas/ra/ra4/r7fa4l1bx.dtsi:237 */
			i2c {
				compatible = "renesas,ra-i2c-sci"; /* in zephyr/dts/arm/renesas/ra/ra4/r7fa4l1bx.dtsi:238 */
				#address-cells = < 0x1 >;          /* in zephyr/dts/arm/renesas/ra/ra4/r7fa4l1bx.dtsi:239 */
				#size-cells = < 0x0 >;             /* in zephyr/dts/arm/renesas/ra/ra4/r7fa4l1bx.dtsi:240 */
				channel = < 0x4 >;                 /* in zephyr/dts/arm/renesas/ra/ra4/r7fa4l1bx.dtsi:241 */
				status = "disabled";               /* in zephyr/dts/arm/renesas/ra/ra4/r7fa4l1bx.dtsi:242 */
			};
		};

		/* node '/soc/sci@40118500' defined in zephyr/dts/arm/renesas/ra/ra4/r7fa4l1bx.dtsi:246 */
		sci5: sci@40118500 {
			compatible = "renesas,ra-sci"; /* in zephyr/dts/arm/renesas/ra/ra4/r7fa4l1bx.dtsi:247 */
			interrupts = < 0x4 0x1 >,
			             < 0x5 0x1 >,
			             < 0x6 0x1 >,
			             < 0x7 0x1 >;      /* in zephyr/dts/arm/renesas/ra/ra4/r7fa4l1bx.dtsi:248 */
			interrupt-names = "rxi",
			                  "txi",
			                  "tei",
			                  "eri";       /* in zephyr/dts/arm/renesas/ra/ra4/r7fa4l1bx.dtsi:249 */
			reg = < 0x40118500 0x100 >;    /* in zephyr/dts/arm/renesas/ra/ra4/r7fa4l1bx.dtsi:250 */
			clocks = < &pclka 0x1 0x1a >;  /* in zephyr/dts/arm/renesas/ra/ra4/r7fa4l1bx.dtsi:251 */
			pinctrl-0 = < &sci5_default >; /* in zephyr/boards/renesas/ek_ra4l1/ek_ra4l1.dts:114 */
			pinctrl-names = "default";     /* in zephyr/boards/renesas/ek_ra4l1/ek_ra4l1.dts:115 */
			status = "okay";               /* in zephyr/boards/renesas/ek_ra4l1/ek_ra4l1.dts:116 */

			/* node '/soc/sci@40118500/uart' defined in zephyr/dts/arm/renesas/ra/ra4/r7fa4l1bx.dtsi:254 */
			uart5: uart {
				compatible = "renesas,ra-sci-uart"; /* in zephyr/dts/arm/renesas/ra/ra4/r7fa4l1bx.dtsi:255 */
				channel = < 0x5 >;                  /* in zephyr/dts/arm/renesas/ra/ra4/r7fa4l1bx.dtsi:256 */
				current-speed = < 0x1c200 >;        /* in zephyr/boards/renesas/ek_ra4l1/ek_ra4l1.dts:119 */
				status = "okay";                    /* in zephyr/boards/renesas/ek_ra4l1/ek_ra4l1.dts:120 */
			};

			/* node '/soc/sci@40118500/i2c' defined in zephyr/dts/arm/renesas/ra/ra4/r7fa4l1bx.dtsi:260 */
			i2c {
				compatible = "renesas,ra-i2c-sci"; /* in zephyr/dts/arm/renesas/ra/ra4/r7fa4l1bx.dtsi:261 */
				#address-cells = < 0x1 >;          /* in zephyr/dts/arm/renesas/ra/ra4/r7fa4l1bx.dtsi:262 */
				#size-cells = < 0x0 >;             /* in zephyr/dts/arm/renesas/ra/ra4/r7fa4l1bx.dtsi:263 */
				channel = < 0x5 >;                 /* in zephyr/dts/arm/renesas/ra/ra4/r7fa4l1bx.dtsi:264 */
				status = "disabled";               /* in zephyr/dts/arm/renesas/ra/ra4/r7fa4l1bx.dtsi:265 */
			};
		};

		/* node '/soc/sci@40118900' defined in zephyr/dts/arm/renesas/ra/ra4/r7fa4l1bx.dtsi:269 */
		sci9: sci@40118900 {
			compatible = "renesas,ra-sci"; /* in zephyr/dts/arm/renesas/ra/ra4/r7fa4l1bx.dtsi:270 */
			interrupts = < 0x18 0x1 >,
			             < 0x19 0x1 >,
			             < 0x1a 0x1 >,
			             < 0x1b 0x1 >;     /* in zephyr/dts/arm/renesas/ra/ra4/r7fa4l1bx.dtsi:271 */
			interrupt-names = "rxi",
			                  "txi",
			                  "tei",
			                  "eri";       /* in zephyr/dts/arm/renesas/ra/ra4/r7fa4l1bx.dtsi:272 */
			reg = < 0x40118900 0x100 >;    /* in zephyr/dts/arm/renesas/ra/ra4/r7fa4l1bx.dtsi:273 */
			clocks = < &pclka 0x1 0x16 >;  /* in zephyr/dts/arm/renesas/ra/ra4/r7fa4l1bx.dtsi:274 */
			status = "disabled";           /* in zephyr/dts/arm/renesas/ra/ra4/r7fa4l1bx.dtsi:275 */

			/* node '/soc/sci@40118900/uart' defined in zephyr/dts/arm/renesas/ra/ra4/r7fa4l1bx.dtsi:277 */
			uart {
				compatible = "renesas,ra-sci-uart"; /* in zephyr/dts/arm/renesas/ra/ra4/r7fa4l1bx.dtsi:278 */
				channel = < 0x9 >;                  /* in zephyr/dts/arm/renesas/ra/ra4/r7fa4l1bx.dtsi:279 */
				status = "disabled";                /* in zephyr/dts/arm/renesas/ra/ra4/r7fa4l1bx.dtsi:280 */
			};

			/* node '/soc/sci@40118900/i2c' defined in zephyr/dts/arm/renesas/ra/ra4/r7fa4l1bx.dtsi:283 */
			i2c {
				compatible = "renesas,ra-i2c-sci"; /* in zephyr/dts/arm/renesas/ra/ra4/r7fa4l1bx.dtsi:284 */
				#address-cells = < 0x1 >;          /* in zephyr/dts/arm/renesas/ra/ra4/r7fa4l1bx.dtsi:285 */
				#size-cells = < 0x0 >;             /* in zephyr/dts/arm/renesas/ra/ra4/r7fa4l1bx.dtsi:286 */
				channel = < 0x9 >;                 /* in zephyr/dts/arm/renesas/ra/ra4/r7fa4l1bx.dtsi:287 */
				status = "disabled";               /* in zephyr/dts/arm/renesas/ra/ra4/r7fa4l1bx.dtsi:288 */
			};
		};

		/* node '/soc/spi@4011a000' defined in zephyr/dts/arm/renesas/ra/ra4/r7fa4l1bx.dtsi:292 */
		spi0: spi@4011a000 {
			compatible = "renesas,ra-spi"; /* in zephyr/dts/arm/renesas/ra/ra4/r7fa4l1bx.dtsi:293 */
			#address-cells = < 0x1 >;      /* in zephyr/dts/arm/renesas/ra/ra4/r7fa4l1bx.dtsi:294 */
			#size-cells = < 0x0 >;         /* in zephyr/dts/arm/renesas/ra/ra4/r7fa4l1bx.dtsi:295 */
			channel = < 0x0 >;             /* in zephyr/dts/arm/renesas/ra/ra4/r7fa4l1bx.dtsi:296 */
			interrupts = < 0x1c 0x1 >,
			             < 0x1d 0x1 >,
			             < 0x1e 0x1 >,
			             < 0x1f 0x1 >;     /* in zephyr/dts/arm/renesas/ra/ra4/r7fa4l1bx.dtsi:297 */
			interrupt-names = "rxi",
			                  "txi",
			                  "tei",
			                  "eri";       /* in zephyr/dts/arm/renesas/ra/ra4/r7fa4l1bx.dtsi:298 */
			reg = < 0x4011a000 0x100 >;    /* in zephyr/dts/arm/renesas/ra/ra4/r7fa4l1bx.dtsi:299 */
			pinctrl-0 = < &spi0_default >; /* in zephyr/boards/renesas/ek_ra4l1/ek_ra4l1.dts:145 */
			pinctrl-names = "default";     /* in zephyr/boards/renesas/ek_ra4l1/ek_ra4l1.dts:146 */
			status = "okay";               /* in zephyr/boards/renesas/ek_ra4l1/ek_ra4l1.dts:147 */
		};

		/* node '/soc/i3c@4011f000' defined in zephyr/dts/arm/renesas/ra/ra4/r7fa4l1bx.dtsi:303 */
		i3c0: i3c@4011f000 {
			compatible = "renesas,ra-i3c"; /* in zephyr/dts/arm/renesas/ra/ra4/r7fa4l1bx.dtsi:304 */
			#address-cells = < 0x3 >;      /* in zephyr/dts/arm/renesas/ra/ra4/r7fa4l1bx.dtsi:305 */
			#size-cells = < 0x0 >;         /* in zephyr/dts/arm/renesas/ra/ra4/r7fa4l1bx.dtsi:306 */
			reg = < 0x4011f000 0x3e8 >;    /* in zephyr/dts/arm/renesas/ra/ra4/r7fa4l1bx.dtsi:307 */
			channel = < 0x0 >;             /* in zephyr/dts/arm/renesas/ra/ra4/r7fa4l1bx.dtsi:308 */
			clocks = < &pclka 0x1 0x4 >,
			         < &i3cclk 0x0 0x0 >;  /* in zephyr/dts/arm/renesas/ra/ra4/r7fa4l1bx.dtsi:309 */
			clock-names = "pclk",
			              "tclk";          /* in zephyr/dts/arm/renesas/ra/ra4/r7fa4l1bx.dtsi:310 */
			i2c-scl-hz = < 0x61a80 >;      /* in zephyr/boards/renesas/ek_ra4l1/ek_ra4l1.dts:151 */
			i3c-scl-hz = < 0x3d0900 >;     /* in zephyr/boards/renesas/ek_ra4l1/ek_ra4l1.dts:152 */
			pinctrl-0 = < &i3c0_default >; /* in zephyr/boards/renesas/ek_ra4l1/ek_ra4l1.dts:153 */
			pinctrl-names = "default";     /* in zephyr/boards/renesas/ek_ra4l1/ek_ra4l1.dts:154 */
			interrupts = < 0x20 0x1 >,
			             < 0x21 0x1 >,
			             < 0x22 0x1 >,
			             < 0x23 0x1 >,
			             < 0x24 0x1 >,
			             < 0x25 0x1 >;     /* in zephyr/boards/renesas/ek_ra4l1/ek_ra4l1.dts:155 */
			interrupt-names = "resp",
			                  "rx",
			                  "tx",
			                  "rcv",
			                  "ibi",
			                  "eei";       /* in zephyr/boards/renesas/ek_ra4l1/ek_ra4l1.dts:156 */
			status = "okay";               /* in zephyr/boards/renesas/ek_ra4l1/ek_ra4l1.dts:157 */
		};

		/* node '/soc/adc@40170000' defined in zephyr/dts/arm/renesas/ra/ra4/r7fa4l1bx.dtsi:314 */
		adc0: adc@40170000 {
			compatible = "renesas,ra-adc";          /* in zephyr/dts/arm/renesas/ra/ra4/r7fa4l1bx.dtsi:315 */
			interrupts = < 0x26 0x1 >;              /* in zephyr/dts/arm/renesas/ra/ra4/r7fa4l1bx.dtsi:316 */
			interrupt-names = "scanend";            /* in zephyr/dts/arm/renesas/ra/ra4/r7fa4l1bx.dtsi:317 */
			reg = < 0x40170000 0x100 >;             /* in zephyr/dts/arm/renesas/ra/ra4/r7fa4l1bx.dtsi:318 */
			#io-channel-cells = < 0x1 >;            /* in zephyr/dts/arm/renesas/ra/ra4/r7fa4l1bx.dtsi:319 */
			vref-mv = < 0xce4 >;                    /* in zephyr/dts/arm/renesas/ra/ra4/r7fa4l1bx.dtsi:320 */
			channel-available-mask = < 0x3fe007f >; /* in zephyr/dts/arm/renesas/ra/ra4/r7fa4l1bx.dtsi:321 */
			status = "okay";                        /* in zephyr/boards/renesas/ek_ra4l1/ek_ra4l1.dts:161 */
			pinctrl-0 = < &adc0_default >;          /* in zephyr/boards/renesas/ek_ra4l1/ek_ra4l1.dts:162 */
			pinctrl-names = "default";              /* in zephyr/boards/renesas/ek_ra4l1/ek_ra4l1.dts:163 */
		};

		/* node '/soc/dac_global@40171000' defined in zephyr/dts/arm/renesas/ra/ra4/r7fa4l1bx.dtsi:325 */
		dac_global: dac_global@40171000 {
			compatible = "renesas,ra-dac-global"; /* in zephyr/dts/arm/renesas/ra/ra4/r7fa4l1bx.dtsi:326 */
			reg = < 0x40171000 0x10c4 >;          /* in zephyr/dts/arm/renesas/ra/ra4/r7fa4l1bx.dtsi:327 */
			#address-cells = < 0x1 >;             /* in zephyr/dts/arm/renesas/ra/ra4/r7fa4l1bx.dtsi:328 */
			#size-cells = < 0x0 >;                /* in zephyr/dts/arm/renesas/ra/ra4/r7fa4l1bx.dtsi:329 */
			has-davrefcr;                         /* in zephyr/dts/arm/renesas/ra/ra4/r7fa4l1bx.dtsi:330 */

			/* node '/soc/dac_global@40171000/dac@0' defined in zephyr/dts/arm/renesas/ra/ra4/r7fa4l1bx.dtsi:332 */
			dac0: dac@0 {
				compatible = "renesas,ra-dac"; /* in zephyr/dts/arm/renesas/ra/ra4/r7fa4l1bx.dtsi:333 */
				#io-channel-cells = < 0x1 >;   /* in zephyr/dts/arm/renesas/ra/ra4/r7fa4l1bx.dtsi:334 */
				reg = < 0x0 >;                 /* in zephyr/dts/arm/renesas/ra/ra4/r7fa4l1bx.dtsi:335 */
				pinctrl-0 = < &dac0_default >; /* in zephyr/boards/renesas/ek_ra4l1/ek_ra4l1.dts:167 */
				pinctrl-names = "default";     /* in zephyr/boards/renesas/ek_ra4l1/ek_ra4l1.dts:168 */
				status = "okay";               /* in zephyr/boards/renesas/ek_ra4l1/ek_ra4l1.dts:169 */
			};
		};

		/* node '/soc/crc@40108000' defined in zephyr/dts/arm/renesas/ra/ra4/r7fa4l1bx.dtsi:340 */
		crc: crc@40108000 {
			compatible = "renesas,ra-crc"; /* in zephyr/dts/arm/renesas/ra/ra4/r7fa4l1bx.dtsi:341 */
			reg = < 0x40108000 0x1000 >;   /* in zephyr/dts/arm/renesas/ra/ra4/r7fa4l1bx.dtsi:342 */
			clocks = < &pclka 0x2 0x1 >;   /* in zephyr/dts/arm/renesas/ra/ra4/r7fa4l1bx.dtsi:343 */
			status = "okay";               /* in zephyr/boards/renesas/ek_ra4l1/ek_ra4l1.dts:231 */
		};

		/* node '/soc/iic0@4009f000' defined in zephyr/dts/arm/renesas/ra/ra4/r7fa4l1bx.dtsi:347 */
		iic0: iic0@4009f000 {
			compatible = "renesas,ra-iic"; /* in zephyr/dts/arm/renesas/ra/ra4/r7fa4l1bx.dtsi:348 */
			channel = < 0x0 >;             /* in zephyr/dts/arm/renesas/ra/ra4/r7fa4l1bx.dtsi:349 */
			reg = < 0x4009f000 0x100 >;    /* in zephyr/dts/arm/renesas/ra/ra4/r7fa4l1bx.dtsi:350 */
			pinctrl-0 = < &iic0_default >; /* in zephyr/boards/renesas/ek_ra4l1/ek_ra4l1.dts:191 */
			pinctrl-names = "default";     /* in zephyr/boards/renesas/ek_ra4l1/ek_ra4l1.dts:192 */
			#address-cells = < 0x1 >;      /* in zephyr/boards/renesas/ek_ra4l1/ek_ra4l1.dts:193 */
			#size-cells = < 0x0 >;         /* in zephyr/boards/renesas/ek_ra4l1/ek_ra4l1.dts:194 */
			clock-frequency = < 0xf4240 >; /* in zephyr/boards/renesas/ek_ra4l1/ek_ra4l1.dts:195 */
			interrupts = < 0xa 0x1 >,
			             < 0xb 0x1 >,
			             < 0xc 0x1 >,
			             < 0xd 0x1 >;      /* in zephyr/boards/renesas/ek_ra4l1/ek_ra4l1.dts:196 */
			interrupt-names = "rxi",
			                  "txi",
			                  "tei",
			                  "eri";       /* in zephyr/boards/renesas/ek_ra4l1/ek_ra4l1.dts:197 */
			status = "okay";               /* in zephyr/boards/renesas/ek_ra4l1/ek_ra4l1.dts:198 */
		};

		/* node '/soc/pwm0@40169000' defined in zephyr/dts/arm/renesas/ra/ra4/r7fa4l1bx.dtsi:354 */
		pwm0: pwm0@40169000 {
			compatible = "renesas,ra-pwm"; /* in zephyr/dts/arm/renesas/ra/ra4/r7fa4l1bx.dtsi:355 */
			divider = < 0x0 >;             /* in zephyr/dts/arm/renesas/ra/ra4/r7fa4l1bx.dtsi:356 */
			channel = < 0x0 >;             /* in zephyr/dts/arm/renesas/ra/ra4/r7fa4l1bx.dtsi:357 */
			clocks = < &pclkd 0x4 0x1f >;  /* in zephyr/dts/arm/renesas/ra/ra4/r7fa4l1bx.dtsi:358 */
			reg = < 0x40169000 0x100 >;    /* in zephyr/dts/arm/renesas/ra/ra4/r7fa4l1bx.dtsi:359 */
			#pwm-cells = < 0x3 >;          /* in zephyr/dts/arm/renesas/ra/ra4/r7fa4l1bx.dtsi:360 */
			status = "disabled";           /* in zephyr/dts/arm/renesas/ra/ra4/r7fa4l1bx.dtsi:361 */
		};

		/* node '/soc/pwm1@40169100' defined in zephyr/dts/arm/renesas/ra/ra4/r7fa4l1bx.dtsi:364 */
		pwm1: pwm1@40169100 {
			compatible = "renesas,ra-pwm"; /* in zephyr/dts/arm/renesas/ra/ra4/r7fa4l1bx.dtsi:365 */
			divider = < 0x0 >;             /* in zephyr/dts/arm/renesas/ra/ra4/r7fa4l1bx.dtsi:366 */
			channel = < 0x1 >;             /* in zephyr/dts/arm/renesas/ra/ra4/r7fa4l1bx.dtsi:367 */
			clocks = < &pclkd 0x4 0x1e >;  /* in zephyr/dts/arm/renesas/ra/ra4/r7fa4l1bx.dtsi:368 */
			reg = < 0x40169100 0x100 >;    /* in zephyr/dts/arm/renesas/ra/ra4/r7fa4l1bx.dtsi:369 */
			#pwm-cells = < 0x3 >;          /* in zephyr/dts/arm/renesas/ra/ra4/r7fa4l1bx.dtsi:370 */
			pinctrl-0 = < &pwm1_default >; /* in zephyr/boards/renesas/ek_ra4l1/ek_ra4l1.dts:183 */
			pinctrl-names = "default";     /* in zephyr/boards/renesas/ek_ra4l1/ek_ra4l1.dts:184 */
			interrupts = < 0x8 0x1 >,
			             < 0x9 0x1 >;      /* in zephyr/boards/renesas/ek_ra4l1/ek_ra4l1.dts:185 */
			interrupt-names = "gtioca",
			                  "overflow";  /* in zephyr/boards/renesas/ek_ra4l1/ek_ra4l1.dts:186 */
			status = "okay";               /* in zephyr/boards/renesas/ek_ra4l1/ek_ra4l1.dts:187 */
		};

		/* node '/soc/pwm2@40169200' defined in zephyr/dts/arm/renesas/ra/ra4/r7fa4l1bx.dtsi:374 */
		pwm2: pwm2@40169200 {
			compatible = "renesas,ra-pwm"; /* in zephyr/dts/arm/renesas/ra/ra4/r7fa4l1bx.dtsi:375 */
			divider = < 0x0 >;             /* in zephyr/dts/arm/renesas/ra/ra4/r7fa4l1bx.dtsi:376 */
			channel = < 0x2 >;             /* in zephyr/dts/arm/renesas/ra/ra4/r7fa4l1bx.dtsi:377 */
			clocks = < &pclkd 0x4 0x1d >;  /* in zephyr/dts/arm/renesas/ra/ra4/r7fa4l1bx.dtsi:378 */
			reg = < 0x40169200 0x100 >;    /* in zephyr/dts/arm/renesas/ra/ra4/r7fa4l1bx.dtsi:379 */
			#pwm-cells = < 0x3 >;          /* in zephyr/dts/arm/renesas/ra/ra4/r7fa4l1bx.dtsi:380 */
			status = "disabled";           /* in zephyr/dts/arm/renesas/ra/ra4/r7fa4l1bx.dtsi:381 */
		};

		/* node '/soc/pwm3@40169300' defined in zephyr/dts/arm/renesas/ra/ra4/r7fa4l1bx.dtsi:384 */
		pwm3: pwm3@40169300 {
			compatible = "renesas,ra-pwm"; /* in zephyr/dts/arm/renesas/ra/ra4/r7fa4l1bx.dtsi:385 */
			divider = < 0x0 >;             /* in zephyr/dts/arm/renesas/ra/ra4/r7fa4l1bx.dtsi:386 */
			channel = < 0x3 >;             /* in zephyr/dts/arm/renesas/ra/ra4/r7fa4l1bx.dtsi:387 */
			clocks = < &pclkd 0x4 0x1c >;  /* in zephyr/dts/arm/renesas/ra/ra4/r7fa4l1bx.dtsi:388 */
			reg = < 0x40169300 0x100 >;    /* in zephyr/dts/arm/renesas/ra/ra4/r7fa4l1bx.dtsi:389 */
			#pwm-cells = < 0x3 >;          /* in zephyr/dts/arm/renesas/ra/ra4/r7fa4l1bx.dtsi:390 */
			status = "disabled";           /* in zephyr/dts/arm/renesas/ra/ra4/r7fa4l1bx.dtsi:391 */
		};

		/* node '/soc/pwm4@40169400' defined in zephyr/dts/arm/renesas/ra/ra4/r7fa4l1bx.dtsi:394 */
		pwm4: pwm4@40169400 {
			compatible = "renesas,ra-pwm"; /* in zephyr/dts/arm/renesas/ra/ra4/r7fa4l1bx.dtsi:395 */
			divider = < 0x0 >;             /* in zephyr/dts/arm/renesas/ra/ra4/r7fa4l1bx.dtsi:396 */
			channel = < 0x4 >;             /* in zephyr/dts/arm/renesas/ra/ra4/r7fa4l1bx.dtsi:397 */
			clocks = < &pclkd 0x4 0x1b >;  /* in zephyr/dts/arm/renesas/ra/ra4/r7fa4l1bx.dtsi:398 */
			reg = < 0x40169400 0x100 >;    /* in zephyr/dts/arm/renesas/ra/ra4/r7fa4l1bx.dtsi:399 */
			#pwm-cells = < 0x3 >;          /* in zephyr/dts/arm/renesas/ra/ra4/r7fa4l1bx.dtsi:400 */
			status = "disabled";           /* in zephyr/dts/arm/renesas/ra/ra4/r7fa4l1bx.dtsi:401 */
		};

		/* node '/soc/pwm5@40169500' defined in zephyr/dts/arm/renesas/ra/ra4/r7fa4l1bx.dtsi:404 */
		pwm5: pwm5@40169500 {
			compatible = "renesas,ra-pwm"; /* in zephyr/dts/arm/renesas/ra/ra4/r7fa4l1bx.dtsi:405 */
			divider = < 0x0 >;             /* in zephyr/dts/arm/renesas/ra/ra4/r7fa4l1bx.dtsi:406 */
			channel = < 0x5 >;             /* in zephyr/dts/arm/renesas/ra/ra4/r7fa4l1bx.dtsi:407 */
			clocks = < &pclkd 0x4 0x1a >;  /* in zephyr/dts/arm/renesas/ra/ra4/r7fa4l1bx.dtsi:408 */
			reg = < 0x40169500 0x100 >;    /* in zephyr/dts/arm/renesas/ra/ra4/r7fa4l1bx.dtsi:409 */
			#pwm-cells = < 0x3 >;          /* in zephyr/dts/arm/renesas/ra/ra4/r7fa4l1bx.dtsi:410 */
			status = "disabled";           /* in zephyr/dts/arm/renesas/ra/ra4/r7fa4l1bx.dtsi:411 */
		};

		/* node '/soc/canfd_global@400b0000' defined in zephyr/dts/arm/renesas/ra/ra4/r7fa4l1bx.dtsi:414 */
		canfd_global: canfd_global@400b0000 {
			compatible = "renesas,ra-canfd-global"; /* in zephyr/dts/arm/renesas/ra/ra4/r7fa4l1bx.dtsi:415 */
			interrupts = < 0x28 0x1 >,
			             < 0x29 0x1 >;              /* in zephyr/dts/arm/renesas/ra/ra4/r7fa4l1bx.dtsi:416 */
			interrupt-names = "rxf",
			                  "glerr";              /* in zephyr/dts/arm/renesas/ra/ra4/r7fa4l1bx.dtsi:417 */
			clocks = < &pclkb 0x0 0x0 >,
			         < &pclka 0x0 0x0 >;            /* in zephyr/dts/arm/renesas/ra/ra4/r7fa4l1bx.dtsi:418 */
			clock-names = "opclk",
			              "ramclk";                 /* in zephyr/dts/arm/renesas/ra/ra4/r7fa4l1bx.dtsi:419 */
			reg = < 0x400b0000 0x2000 >;            /* in zephyr/dts/arm/renesas/ra/ra4/r7fa4l1bx.dtsi:420 */
			status = "okay";                        /* in zephyr/boards/renesas/ek_ra4l1/ek_ra4l1.dts:202 */

			/* node '/soc/canfd_global@400b0000/canfd0' defined in zephyr/dts/arm/renesas/ra/ra4/r7fa4l1bx.dtsi:423 */
			canfd0: canfd0 {
				compatible = "renesas,ra-canfd"; /* in zephyr/dts/arm/renesas/ra/ra4/r7fa4l1bx.dtsi:424 */
				channel = < 0x0 >;               /* in zephyr/dts/arm/renesas/ra/ra4/r7fa4l1bx.dtsi:425 */
				interrupts = < 0x2b 0xc >,
				             < 0x2c 0xc >,
				             < 0x2d 0xc >;       /* in zephyr/dts/arm/renesas/ra/ra4/r7fa4l1bx.dtsi:426 */
				interrupt-names = "err",
				                  "tx",
				                  "rx";          /* in zephyr/dts/arm/renesas/ra/ra4/r7fa4l1bx.dtsi:427 */
				clocks = < &canfdclk 0x2 0x1b >; /* in zephyr/dts/arm/renesas/ra/ra4/r7fa4l1bx.dtsi:428 */
				clock-names = "dllclk";          /* in zephyr/dts/arm/renesas/ra/ra4/r7fa4l1bx.dtsi:429 */
				pinctrl-0 = < &canfd0_default >; /* in zephyr/boards/renesas/ek_ra4l1/ek_ra4l1.dts:205 */
				pinctrl-names = "default";       /* in zephyr/boards/renesas/ek_ra4l1/ek_ra4l1.dts:206 */
				phys = < &transceiver0 >;        /* in zephyr/boards/renesas/ek_ra4l1/ek_ra4l1.dts:207 */
				rx-max-filters = < 0x10 >;       /* in zephyr/boards/renesas/ek_ra4l1/ek_ra4l1.dts:208 */
				status = "okay";                 /* in zephyr/boards/renesas/ek_ra4l1/ek_ra4l1.dts:209 */
			};
		};

		/* node '/soc/external-interrupt@40006000' defined in zephyr/dts/arm/renesas/ra/ra4/r7fa4l1bx.dtsi:434 */
		port_irq0: external-interrupt@40006000 {
			compatible = "renesas,ra-external-interrupt"; /* in zephyr/dts/arm/renesas/ra/ra4/r7fa4l1bx.dtsi:435 */
			reg = < 0x40006000 0x1 >;                     /* in zephyr/dts/arm/renesas/ra/ra4/r7fa4l1bx.dtsi:436 */
			channel = < 0x0 >;                            /* in zephyr/dts/arm/renesas/ra/ra4/r7fa4l1bx.dtsi:437 */
			renesas,sample-clock-div = < 0x40 >;          /* in zephyr/dts/arm/renesas/ra/ra4/r7fa4l1bx.dtsi:438 */
			#port-irq-cells = < 0x0 >;                    /* in zephyr/dts/arm/renesas/ra/ra4/r7fa4l1bx.dtsi:439 */
			status = "disabled";                          /* in zephyr/dts/arm/renesas/ra/ra4/r7fa4l1bx.dtsi:440 */
			phandle = < 0x9 >;                            /* in zephyr/dts/arm/renesas/ra/ra4/r7fa4l1bx.dtsi:860 */
		};

		/* node '/soc/external-interrupt@40006001' defined in zephyr/dts/arm/renesas/ra/ra4/r7fa4l1bx.dtsi:443 */
		port_irq1: external-interrupt@40006001 {
			compatible = "renesas,ra-external-interrupt"; /* in zephyr/dts/arm/renesas/ra/ra4/r7fa4l1bx.dtsi:444 */
			reg = < 0x40006001 0x1 >;                     /* in zephyr/dts/arm/renesas/ra/ra4/r7fa4l1bx.dtsi:445 */
			channel = < 0x1 >;                            /* in zephyr/dts/arm/renesas/ra/ra4/r7fa4l1bx.dtsi:446 */
			renesas,sample-clock-div = < 0x40 >;          /* in zephyr/dts/arm/renesas/ra/ra4/r7fa4l1bx.dtsi:447 */
			#port-irq-cells = < 0x0 >;                    /* in zephyr/dts/arm/renesas/ra/ra4/r7fa4l1bx.dtsi:448 */
			status = "disabled";                          /* in zephyr/dts/arm/renesas/ra/ra4/r7fa4l1bx.dtsi:449 */
			phandle = < 0xa >;                            /* in zephyr/dts/arm/renesas/ra/ra4/r7fa4l1bx.dtsi:860 */
		};

		/* node '/soc/external-interrupt@40006002' defined in zephyr/dts/arm/renesas/ra/ra4/r7fa4l1bx.dtsi:452 */
		port_irq2: external-interrupt@40006002 {
			compatible = "renesas,ra-external-interrupt"; /* in zephyr/dts/arm/renesas/ra/ra4/r7fa4l1bx.dtsi:453 */
			reg = < 0x40006002 0x1 >;                     /* in zephyr/dts/arm/renesas/ra/ra4/r7fa4l1bx.dtsi:454 */
			channel = < 0x2 >;                            /* in zephyr/dts/arm/renesas/ra/ra4/r7fa4l1bx.dtsi:455 */
			renesas,sample-clock-div = < 0x40 >;          /* in zephyr/dts/arm/renesas/ra/ra4/r7fa4l1bx.dtsi:456 */
			#port-irq-cells = < 0x0 >;                    /* in zephyr/dts/arm/renesas/ra/ra4/r7fa4l1bx.dtsi:457 */
			status = "disabled";                          /* in zephyr/dts/arm/renesas/ra/ra4/r7fa4l1bx.dtsi:458 */
			phandle = < 0xb >;                            /* in zephyr/dts/arm/renesas/ra/ra4/r7fa4l1bx.dtsi:860 */
		};

		/* node '/soc/external-interrupt@40006003' defined in zephyr/dts/arm/renesas/ra/ra4/r7fa4l1bx.dtsi:461 */
		port_irq3: external-interrupt@40006003 {
			compatible = "renesas,ra-external-interrupt"; /* in zephyr/dts/arm/renesas/ra/ra4/r7fa4l1bx.dtsi:462 */
			reg = < 0x40006003 0x1 >;                     /* in zephyr/dts/arm/renesas/ra/ra4/r7fa4l1bx.dtsi:463 */
			channel = < 0x3 >;                            /* in zephyr/dts/arm/renesas/ra/ra4/r7fa4l1bx.dtsi:464 */
			renesas,sample-clock-div = < 0x40 >;          /* in zephyr/dts/arm/renesas/ra/ra4/r7fa4l1bx.dtsi:465 */
			#port-irq-cells = < 0x0 >;                    /* in zephyr/dts/arm/renesas/ra/ra4/r7fa4l1bx.dtsi:466 */
			status = "disabled";                          /* in zephyr/dts/arm/renesas/ra/ra4/r7fa4l1bx.dtsi:467 */
			phandle = < 0xc >;                            /* in zephyr/dts/arm/renesas/ra/ra4/r7fa4l1bx.dtsi:860 */
		};

		/* node '/soc/external-interrupt@40006004' defined in zephyr/dts/arm/renesas/ra/ra4/r7fa4l1bx.dtsi:470 */
		port_irq4: external-interrupt@40006004 {
			compatible = "renesas,ra-external-interrupt"; /* in zephyr/dts/arm/renesas/ra/ra4/r7fa4l1bx.dtsi:471 */
			reg = < 0x40006004 0x1 >;                     /* in zephyr/dts/arm/renesas/ra/ra4/r7fa4l1bx.dtsi:472 */
			channel = < 0x4 >;                            /* in zephyr/dts/arm/renesas/ra/ra4/r7fa4l1bx.dtsi:473 */
			renesas,sample-clock-div = < 0x40 >;          /* in zephyr/dts/arm/renesas/ra/ra4/r7fa4l1bx.dtsi:474 */
			#port-irq-cells = < 0x0 >;                    /* in zephyr/dts/arm/renesas/ra/ra4/r7fa4l1bx.dtsi:475 */
			status = "disabled";                          /* in zephyr/dts/arm/renesas/ra/ra4/r7fa4l1bx.dtsi:476 */
			phandle = < 0xd >;                            /* in zephyr/dts/arm/renesas/ra/ra4/r7fa4l1bx.dtsi:860 */
		};

		/* node '/soc/external-interrupt@40006005' defined in zephyr/dts/arm/renesas/ra/ra4/r7fa4l1bx.dtsi:479 */
		port_irq5: external-interrupt@40006005 {
			compatible = "renesas,ra-external-interrupt"; /* in zephyr/dts/arm/renesas/ra/ra4/r7fa4l1bx.dtsi:480 */
			reg = < 0x40006005 0x1 >;                     /* in zephyr/dts/arm/renesas/ra/ra4/r7fa4l1bx.dtsi:481 */
			channel = < 0x5 >;                            /* in zephyr/dts/arm/renesas/ra/ra4/r7fa4l1bx.dtsi:482 */
			renesas,sample-clock-div = < 0x40 >;          /* in zephyr/dts/arm/renesas/ra/ra4/r7fa4l1bx.dtsi:483 */
			#port-irq-cells = < 0x0 >;                    /* in zephyr/dts/arm/renesas/ra/ra4/r7fa4l1bx.dtsi:484 */
			status = "disabled";                          /* in zephyr/dts/arm/renesas/ra/ra4/r7fa4l1bx.dtsi:485 */
			phandle = < 0xf >;                            /* in zephyr/dts/arm/renesas/ra/ra4/r7fa4l1bx.dtsi:890 */
		};

		/* node '/soc/external-interrupt@40006006' defined in zephyr/dts/arm/renesas/ra/ra4/r7fa4l1bx.dtsi:488 */
		port_irq6: external-interrupt@40006006 {
			compatible = "renesas,ra-external-interrupt"; /* in zephyr/dts/arm/renesas/ra/ra4/r7fa4l1bx.dtsi:489 */
			reg = < 0x40006006 0x1 >;                     /* in zephyr/dts/arm/renesas/ra/ra4/r7fa4l1bx.dtsi:490 */
			channel = < 0x6 >;                            /* in zephyr/dts/arm/renesas/ra/ra4/r7fa4l1bx.dtsi:491 */
			renesas,sample-clock-div = < 0x40 >;          /* in zephyr/dts/arm/renesas/ra/ra4/r7fa4l1bx.dtsi:492 */
			#port-irq-cells = < 0x0 >;                    /* in zephyr/dts/arm/renesas/ra/ra4/r7fa4l1bx.dtsi:493 */
			interrupts = < 0xe 0xc >;                     /* in zephyr/boards/renesas/ek_ra4l1/ek_ra4l1.dts:173 */
			status = "okay";                              /* in zephyr/boards/renesas/ek_ra4l1/ek_ra4l1.dts:174 */
			phandle = < 0x3 >;                            /* in zephyr/dts/arm/renesas/ra/ra4/r7fa4l1bx.dtsi:843 */
		};

		/* node '/soc/external-interrupt@40006007' defined in zephyr/dts/arm/renesas/ra/ra4/r7fa4l1bx.dtsi:497 */
		port_irq7: external-interrupt@40006007 {
			compatible = "renesas,ra-external-interrupt"; /* in zephyr/dts/arm/renesas/ra/ra4/r7fa4l1bx.dtsi:498 */
			reg = < 0x40006007 0x1 >;                     /* in zephyr/dts/arm/renesas/ra/ra4/r7fa4l1bx.dtsi:499 */
			channel = < 0x7 >;                            /* in zephyr/dts/arm/renesas/ra/ra4/r7fa4l1bx.dtsi:500 */
			renesas,sample-clock-div = < 0x40 >;          /* in zephyr/dts/arm/renesas/ra/ra4/r7fa4l1bx.dtsi:501 */
			#port-irq-cells = < 0x0 >;                    /* in zephyr/dts/arm/renesas/ra/ra4/r7fa4l1bx.dtsi:502 */
			interrupts = < 0xf 0xc >;                     /* in zephyr/boards/renesas/ek_ra4l1/ek_ra4l1.dts:178 */
			status = "okay";                              /* in zephyr/boards/renesas/ek_ra4l1/ek_ra4l1.dts:179 */
			phandle = < 0x4 >;                            /* in zephyr/dts/arm/renesas/ra/ra4/r7fa4l1bx.dtsi:843 */
		};

		/* node '/soc/external-interrupt@40006008' defined in zephyr/dts/arm/renesas/ra/ra4/r7fa4l1bx.dtsi:506 */
		port_irq8: external-interrupt@40006008 {
			compatible = "renesas,ra-external-interrupt"; /* in zephyr/dts/arm/renesas/ra/ra4/r7fa4l1bx.dtsi:507 */
			reg = < 0x40006008 0x1 >;                     /* in zephyr/dts/arm/renesas/ra/ra4/r7fa4l1bx.dtsi:508 */
			channel = < 0x8 >;                            /* in zephyr/dts/arm/renesas/ra/ra4/r7fa4l1bx.dtsi:509 */
			renesas,sample-clock-div = < 0x40 >;          /* in zephyr/dts/arm/renesas/ra/ra4/r7fa4l1bx.dtsi:510 */
			#port-irq-cells = < 0x0 >;                    /* in zephyr/dts/arm/renesas/ra/ra4/r7fa4l1bx.dtsi:511 */
			status = "disabled";                          /* in zephyr/dts/arm/renesas/ra/ra4/r7fa4l1bx.dtsi:512 */
			phandle = < 0x5 >;                            /* in zephyr/dts/arm/renesas/ra/ra4/r7fa4l1bx.dtsi:843 */
		};

		/* node '/soc/external-interrupt@40006009' defined in zephyr/dts/arm/renesas/ra/ra4/r7fa4l1bx.dtsi:515 */
		port_irq9: external-interrupt@40006009 {
			compatible = "renesas,ra-external-interrupt"; /* in zephyr/dts/arm/renesas/ra/ra4/r7fa4l1bx.dtsi:516 */
			reg = < 0x40006009 0x1 >;                     /* in zephyr/dts/arm/renesas/ra/ra4/r7fa4l1bx.dtsi:517 */
			channel = < 0x9 >;                            /* in zephyr/dts/arm/renesas/ra/ra4/r7fa4l1bx.dtsi:518 */
			renesas,sample-clock-div = < 0x40 >;          /* in zephyr/dts/arm/renesas/ra/ra4/r7fa4l1bx.dtsi:519 */
			#port-irq-cells = < 0x0 >;                    /* in zephyr/dts/arm/renesas/ra/ra4/r7fa4l1bx.dtsi:520 */
			status = "disabled";                          /* in zephyr/dts/arm/renesas/ra/ra4/r7fa4l1bx.dtsi:521 */
			phandle = < 0x6 >;                            /* in zephyr/dts/arm/renesas/ra/ra4/r7fa4l1bx.dtsi:843 */
		};

		/* node '/soc/external-interrupt@4000600a' defined in zephyr/dts/arm/renesas/ra/ra4/r7fa4l1bx.dtsi:524 */
		port_irq10: external-interrupt@4000600a {
			compatible = "renesas,ra-external-interrupt"; /* in zephyr/dts/arm/renesas/ra/ra4/r7fa4l1bx.dtsi:525 */
			reg = < 0x4000600a 0x1 >;                     /* in zephyr/dts/arm/renesas/ra/ra4/r7fa4l1bx.dtsi:526 */
			channel = < 0xa >;                            /* in zephyr/dts/arm/renesas/ra/ra4/r7fa4l1bx.dtsi:527 */
			renesas,sample-clock-div = < 0x40 >;          /* in zephyr/dts/arm/renesas/ra/ra4/r7fa4l1bx.dtsi:528 */
			#port-irq-cells = < 0x0 >;                    /* in zephyr/dts/arm/renesas/ra/ra4/r7fa4l1bx.dtsi:529 */
			status = "disabled";                          /* in zephyr/dts/arm/renesas/ra/ra4/r7fa4l1bx.dtsi:530 */
			phandle = < 0x7 >;                            /* in zephyr/dts/arm/renesas/ra/ra4/r7fa4l1bx.dtsi:843 */
		};

		/* node '/soc/external-interrupt@4000600b' defined in zephyr/dts/arm/renesas/ra/ra4/r7fa4l1bx.dtsi:533 */
		port_irq11: external-interrupt@4000600b {
			compatible = "renesas,ra-external-interrupt"; /* in zephyr/dts/arm/renesas/ra/ra4/r7fa4l1bx.dtsi:534 */
			reg = < 0x4000600b 0x1 >;                     /* in zephyr/dts/arm/renesas/ra/ra4/r7fa4l1bx.dtsi:535 */
			channel = < 0xb >;                            /* in zephyr/dts/arm/renesas/ra/ra4/r7fa4l1bx.dtsi:536 */
			renesas,sample-clock-div = < 0x40 >;          /* in zephyr/dts/arm/renesas/ra/ra4/r7fa4l1bx.dtsi:537 */
			#port-irq-cells = < 0x0 >;                    /* in zephyr/dts/arm/renesas/ra/ra4/r7fa4l1bx.dtsi:538 */
			status = "disabled";                          /* in zephyr/dts/arm/renesas/ra/ra4/r7fa4l1bx.dtsi:539 */
			phandle = < 0x8 >;                            /* in zephyr/dts/arm/renesas/ra/ra4/r7fa4l1bx.dtsi:843 */
		};

		/* node '/soc/external-interrupt@4000600c' defined in zephyr/dts/arm/renesas/ra/ra4/r7fa4l1bx.dtsi:542 */
		port_irq12: external-interrupt@4000600c {
			compatible = "renesas,ra-external-interrupt"; /* in zephyr/dts/arm/renesas/ra/ra4/r7fa4l1bx.dtsi:543 */
			reg = < 0x4000600c 0x1 >;                     /* in zephyr/dts/arm/renesas/ra/ra4/r7fa4l1bx.dtsi:544 */
			channel = < 0xc >;                            /* in zephyr/dts/arm/renesas/ra/ra4/r7fa4l1bx.dtsi:545 */
			renesas,sample-clock-div = < 0x40 >;          /* in zephyr/dts/arm/renesas/ra/ra4/r7fa4l1bx.dtsi:546 */
			#port-irq-cells = < 0x0 >;                    /* in zephyr/dts/arm/renesas/ra/ra4/r7fa4l1bx.dtsi:547 */
			status = "disabled";                          /* in zephyr/dts/arm/renesas/ra/ra4/r7fa4l1bx.dtsi:548 */
			phandle = < 0xe >;                            /* in zephyr/dts/arm/renesas/ra/ra4/r7fa4l1bx.dtsi:875 */
		};

		/* node '/soc/external-interrupt@4000600d' defined in zephyr/dts/arm/renesas/ra/ra4/r7fa4l1bx.dtsi:551 */
		port_irq13: external-interrupt@4000600d {
			compatible = "renesas,ra-external-interrupt"; /* in zephyr/dts/arm/renesas/ra/ra4/r7fa4l1bx.dtsi:552 */
			reg = < 0x4000600d 0x1 >;                     /* in zephyr/dts/arm/renesas/ra/ra4/r7fa4l1bx.dtsi:553 */
			channel = < 0xd >;                            /* in zephyr/dts/arm/renesas/ra/ra4/r7fa4l1bx.dtsi:554 */
			renesas,sample-clock-div = < 0x40 >;          /* in zephyr/dts/arm/renesas/ra/ra4/r7fa4l1bx.dtsi:555 */
			#port-irq-cells = < 0x0 >;                    /* in zephyr/dts/arm/renesas/ra/ra4/r7fa4l1bx.dtsi:556 */
			status = "disabled";                          /* in zephyr/dts/arm/renesas/ra/ra4/r7fa4l1bx.dtsi:557 */
			phandle = < 0x12 >;                           /* in zephyr/dts/arm/renesas/ra/ra4/r7fa4l1bx.dtsi:927 */
		};

		/* node '/soc/external-interrupt@4000600e' defined in zephyr/dts/arm/renesas/ra/ra4/r7fa4l1bx.dtsi:560 */
		port_irq14: external-interrupt@4000600e {
			compatible = "renesas,ra-external-interrupt"; /* in zephyr/dts/arm/renesas/ra/ra4/r7fa4l1bx.dtsi:561 */
			reg = < 0x4000600e 0x1 >;                     /* in zephyr/dts/arm/renesas/ra/ra4/r7fa4l1bx.dtsi:562 */
			channel = < 0xe >;                            /* in zephyr/dts/arm/renesas/ra/ra4/r7fa4l1bx.dtsi:563 */
			renesas,sample-clock-div = < 0x40 >;          /* in zephyr/dts/arm/renesas/ra/ra4/r7fa4l1bx.dtsi:564 */
			#port-irq-cells = < 0x0 >;                    /* in zephyr/dts/arm/renesas/ra/ra4/r7fa4l1bx.dtsi:565 */
			status = "disabled";                          /* in zephyr/dts/arm/renesas/ra/ra4/r7fa4l1bx.dtsi:566 */
			phandle = < 0x10 >;                           /* in zephyr/dts/arm/renesas/ra/ra4/r7fa4l1bx.dtsi:903 */
		};

		/* node '/soc/external-interrupt@4000600f' defined in zephyr/dts/arm/renesas/ra/ra4/r7fa4l1bx.dtsi:569 */
		port_irq15: external-interrupt@4000600f {
			compatible = "renesas,ra-external-interrupt"; /* in zephyr/dts/arm/renesas/ra/ra4/r7fa4l1bx.dtsi:570 */
			reg = < 0x4000600f 0x1 >;                     /* in zephyr/dts/arm/renesas/ra/ra4/r7fa4l1bx.dtsi:571 */
			channel = < 0xf >;                            /* in zephyr/dts/arm/renesas/ra/ra4/r7fa4l1bx.dtsi:572 */
			renesas,sample-clock-div = < 0x40 >;          /* in zephyr/dts/arm/renesas/ra/ra4/r7fa4l1bx.dtsi:573 */
			#port-irq-cells = < 0x0 >;                    /* in zephyr/dts/arm/renesas/ra/ra4/r7fa4l1bx.dtsi:574 */
			status = "disabled";                          /* in zephyr/dts/arm/renesas/ra/ra4/r7fa4l1bx.dtsi:575 */
			phandle = < 0x11 >;                           /* in zephyr/dts/arm/renesas/ra/ra4/r7fa4l1bx.dtsi:903 */
		};

		/* node '/soc/wdt@40083400' defined in zephyr/dts/arm/renesas/ra/ra4/r7fa4l1bx.dtsi:578 */
		wdt: wdt@40083400 {
			compatible = "renesas,ra-wdt"; /* in zephyr/dts/arm/renesas/ra/ra4/r7fa4l1bx.dtsi:579 */
			reg = < 0x40083400 0x200 >;    /* in zephyr/dts/arm/renesas/ra/ra4/r7fa4l1bx.dtsi:580 */
			clocks = < &pclkb 0x0 0x0 >;   /* in zephyr/dts/arm/renesas/ra/ra4/r7fa4l1bx.dtsi:581 */
			status = "okay";               /* in zephyr/boards/renesas/ek_ra4l1/ek_ra4l1.dts:214 */
		};

		/* node '/soc/agtw@400e8000' defined in zephyr/dts/arm/renesas/ra/ra4/r7fa4l1bx.dtsi:585 */
		agt0: agtw@400e8000 {
			compatible = "renesas,ra-agt";           /* in zephyr/dts/arm/renesas/ra/ra4/r7fa4l1bx.dtsi:586 */
			channel = < 0x0 >;                       /* in zephyr/dts/arm/renesas/ra/ra4/r7fa4l1bx.dtsi:587 */
			reg = < 0x400e8000 0x100 >;              /* in zephyr/dts/arm/renesas/ra/ra4/r7fa4l1bx.dtsi:588 */
			renesas,count-source = "AGT_CLOCK_LOCO"; /* in zephyr/dts/arm/renesas/ra/ra4/r7fa4l1bx.dtsi:589 */
			renesas,prescaler = < 0x0 >;             /* in zephyr/dts/arm/renesas/ra/ra4/r7fa4l1bx.dtsi:590 */
			renesas,resolution = < 0x20 >;           /* in zephyr/dts/arm/renesas/ra/ra4/r7fa4l1bx.dtsi:591 */
			status = "disabled";                     /* in zephyr/dts/arm/renesas/ra/ra4/r7fa4l1bx.dtsi:592 */

			/* node '/soc/agtw@400e8000/counter' defined in zephyr/dts/arm/renesas/ra/ra4/r7fa4l1bx.dtsi:594 */
			counter {
				compatible = "renesas,ra-agt-counter"; /* in zephyr/dts/arm/renesas/ra/ra4/r7fa4l1bx.dtsi:595 */
				status = "disabled";                   /* in zephyr/dts/arm/renesas/ra/ra4/r7fa4l1bx.dtsi:596 */
			};
		};

		/* node '/soc/agtw@400e8100' defined in zephyr/dts/arm/renesas/ra/ra4/r7fa4l1bx.dtsi:600 */
		agt1: agtw@400e8100 {
			compatible = "renesas,ra-agt";           /* in zephyr/dts/arm/renesas/ra/ra4/r7fa4l1bx.dtsi:601 */
			channel = < 0x1 >;                       /* in zephyr/dts/arm/renesas/ra/ra4/r7fa4l1bx.dtsi:602 */
			reg = < 0x400e8100 0x100 >;              /* in zephyr/dts/arm/renesas/ra/ra4/r7fa4l1bx.dtsi:603 */
			renesas,count-source = "AGT_CLOCK_LOCO"; /* in zephyr/dts/arm/renesas/ra/ra4/r7fa4l1bx.dtsi:604 */
			renesas,prescaler = < 0x0 >;             /* in zephyr/dts/arm/renesas/ra/ra4/r7fa4l1bx.dtsi:605 */
			renesas,resolution = < 0x20 >;           /* in zephyr/dts/arm/renesas/ra/ra4/r7fa4l1bx.dtsi:606 */
			status = "disabled";                     /* in zephyr/dts/arm/renesas/ra/ra4/r7fa4l1bx.dtsi:607 */

			/* node '/soc/agtw@400e8100/counter' defined in zephyr/dts/arm/renesas/ra/ra4/r7fa4l1bx.dtsi:609 */
			counter {
				compatible = "renesas,ra-agt-counter"; /* in zephyr/dts/arm/renesas/ra/ra4/r7fa4l1bx.dtsi:610 */
				status = "disabled";                   /* in zephyr/dts/arm/renesas/ra/ra4/r7fa4l1bx.dtsi:611 */
			};
		};

		/* node '/soc/ssie@4009d000' defined in zephyr/dts/arm/renesas/ra/ra4/r7fa4l1bx.dtsi:615 */
		i2s0: ssie@4009d000 {
			compatible = "renesas,ra-i2s-ssie"; /* in zephyr/dts/arm/renesas/ra/ra4/r7fa4l1bx.dtsi:616 */
			#address-cells = < 0x1 >;           /* in zephyr/dts/arm/renesas/ra/ra4/r7fa4l1bx.dtsi:617 */
			#size-cells = < 0x0 >;              /* in zephyr/dts/arm/renesas/ra/ra4/r7fa4l1bx.dtsi:618 */
			channel = < 0x0 >;                  /* in zephyr/dts/arm/renesas/ra/ra4/r7fa4l1bx.dtsi:619 */
			reg = < 0x4009d000 0x28 >;          /* in zephyr/dts/arm/renesas/ra/ra4/r7fa4l1bx.dtsi:620 */
			clocks = < &pclkb 0x2 0x8 >;        /* in zephyr/dts/arm/renesas/ra/ra4/r7fa4l1bx.dtsi:621 */
			clock-names = "pclk";               /* in zephyr/dts/arm/renesas/ra/ra4/r7fa4l1bx.dtsi:622 */
			full-duplex;                        /* in zephyr/dts/arm/renesas/ra/ra4/r7fa4l1bx.dtsi:623 */
			status = "disabled";                /* in zephyr/dts/arm/renesas/ra/ra4/r7fa4l1bx.dtsi:624 */
		};

		/* node '/soc/rtc@40083000' defined in zephyr/dts/arm/renesas/ra/ra4/r7fa4l1bx.dtsi:627 */
		rtc: rtc@40083000 {
			compatible = "renesas,ra-rtc"; /* in zephyr/dts/arm/renesas/ra/ra4/r7fa4l1bx.dtsi:628 */
			reg = < 0x2639e38 0x80 >;      /* in zephyr/dts/arm/renesas/ra/ra4/r7fa4l1bx.dtsi:629 */
			clocks = < &subclk >;          /* in zephyr/dts/arm/renesas/ra/ra4/r7fa4l1bx.dtsi:630 */
			alarms-count = < 0x1 >;        /* in zephyr/dts/arm/renesas/ra/ra4/r7fa4l1bx.dtsi:631 */
			status = "disabled";           /* in zephyr/dts/arm/renesas/ra/ra4/r7fa4l1bx.dtsi:632 */
		};

		/* node '/soc/option-setting-ofs0@100a100' defined in zephyr/dts/arm/renesas/ra/ra4/r7fa4l1bx.dtsi:635 */
		option_setting_ofs0: option-setting-ofs0@100a100 {
			compatible = "zephyr,memory-region";      /* in zephyr/dts/arm/renesas/ra/ra4/r7fa4l1bx.dtsi:636 */
			zephyr,memory-region = "OFS_OFS0_MEMORY"; /* in zephyr/dts/arm/renesas/ra/ra4/r7fa4l1bx.dtsi:637 */
			reg = < 0x100a100 0x4 >;                  /* in zephyr/dts/arm/renesas/ra/ra4/r7fa4l1bx.dtsi:638 */
			status = "okay";                          /* in zephyr/dts/arm/renesas/ra/ra4/r7fa4l1bx.dtsi:639 */
		};

		/* node '/soc/option-setting-dualsel@100a110' defined in zephyr/dts/arm/renesas/ra/ra4/r7fa4l1bx.dtsi:642 */
		option_setting_dualsel: option-setting-dualsel@100a110 {
			compatible = "zephyr,memory-region";         /* in zephyr/dts/arm/renesas/ra/ra4/r7fa4l1bx.dtsi:643 */
			zephyr,memory-region = "OFS_DUALSEL_MEMORY"; /* in zephyr/dts/arm/renesas/ra/ra4/r7fa4l1bx.dtsi:644 */
			reg = < 0x100a110 0x4 >;                     /* in zephyr/dts/arm/renesas/ra/ra4/r7fa4l1bx.dtsi:645 */
			status = "okay";                             /* in zephyr/dts/arm/renesas/ra/ra4/r7fa4l1bx.dtsi:646 */
		};

		/* node '/soc/option-setting-ofs1-sec@100a200' defined in zephyr/dts/arm/renesas/ra/ra4/r7fa4l1bx.dtsi:649 */
		option_setting_ofs1_sec: option-setting-ofs1-sec@100a200 {
			compatible = "zephyr,memory-region";          /* in zephyr/dts/arm/renesas/ra/ra4/r7fa4l1bx.dtsi:650 */
			zephyr,memory-region = "OFS_OFS1_SEC_MEMORY"; /* in zephyr/dts/arm/renesas/ra/ra4/r7fa4l1bx.dtsi:651 */
			reg = < 0x100a200 0x4 >;                      /* in zephyr/dts/arm/renesas/ra/ra4/r7fa4l1bx.dtsi:652 */
			status = "okay";                              /* in zephyr/dts/arm/renesas/ra/ra4/r7fa4l1bx.dtsi:653 */
		};

		/* node '/soc/option-setting-banksel-sec@100a210' defined in zephyr/dts/arm/renesas/ra/ra4/r7fa4l1bx.dtsi:656 */
		option_setting_banksel_sec: option-setting-banksel-sec@100a210 {
			compatible = "zephyr,memory-region";             /* in zephyr/dts/arm/renesas/ra/ra4/r7fa4l1bx.dtsi:657 */
			zephyr,memory-region = "OFS_BANKSEL_SEC_MEMORY"; /* in zephyr/dts/arm/renesas/ra/ra4/r7fa4l1bx.dtsi:658 */
			reg = < 0x100a210 0x4 >;                         /* in zephyr/dts/arm/renesas/ra/ra4/r7fa4l1bx.dtsi:659 */
			status = "okay";                                 /* in zephyr/dts/arm/renesas/ra/ra4/r7fa4l1bx.dtsi:660 */
		};

		/* node '/soc/option-setting-bps-sec@100a240' defined in zephyr/dts/arm/renesas/ra/ra4/r7fa4l1bx.dtsi:663 */
		option_setting_bps_sec: option-setting-bps-sec@100a240 {
			compatible = "zephyr,memory-region";         /* in zephyr/dts/arm/renesas/ra/ra4/r7fa4l1bx.dtsi:664 */
			zephyr,memory-region = "OFS_BPS_SEC_MEMORY"; /* in zephyr/dts/arm/renesas/ra/ra4/r7fa4l1bx.dtsi:665 */
			reg = < 0x100a240 0xc >;                     /* in zephyr/dts/arm/renesas/ra/ra4/r7fa4l1bx.dtsi:666 */
			status = "okay";                             /* in zephyr/dts/arm/renesas/ra/ra4/r7fa4l1bx.dtsi:667 */
		};

		/* node '/soc/option-setting-pbps-sec@100a260' defined in zephyr/dts/arm/renesas/ra/ra4/r7fa4l1bx.dtsi:670 */
		option_setting_pbps_sec: option-setting-pbps-sec@100a260 {
			compatible = "zephyr,memory-region";          /* in zephyr/dts/arm/renesas/ra/ra4/r7fa4l1bx.dtsi:671 */
			zephyr,memory-region = "OFS_PBPS_SEC_MEMORY"; /* in zephyr/dts/arm/renesas/ra/ra4/r7fa4l1bx.dtsi:672 */
			reg = < 0x100a260 0xc >;                      /* in zephyr/dts/arm/renesas/ra/ra4/r7fa4l1bx.dtsi:673 */
			status = "okay";                              /* in zephyr/dts/arm/renesas/ra/ra4/r7fa4l1bx.dtsi:674 */
		};

		/* node '/soc/option-setting-ofs1-sel@100a280' defined in zephyr/dts/arm/renesas/ra/ra4/r7fa4l1bx.dtsi:677 */
		option_setting_ofs1_sel: option-setting-ofs1-sel@100a280 {
			compatible = "zephyr,memory-region";          /* in zephyr/dts/arm/renesas/ra/ra4/r7fa4l1bx.dtsi:678 */
			zephyr,memory-region = "OFS_OFS1_SEL_MEMORY"; /* in zephyr/dts/arm/renesas/ra/ra4/r7fa4l1bx.dtsi:679 */
			reg = < 0x100a280 0x4 >;                      /* in zephyr/dts/arm/renesas/ra/ra4/r7fa4l1bx.dtsi:680 */
			status = "okay";                              /* in zephyr/dts/arm/renesas/ra/ra4/r7fa4l1bx.dtsi:681 */
		};

		/* node '/soc/option-setting-banksel-sel@100a290' defined in zephyr/dts/arm/renesas/ra/ra4/r7fa4l1bx.dtsi:684 */
		option_setting_banksel_sel: option-setting-banksel-sel@100a290 {
			compatible = "zephyr,memory-region";             /* in zephyr/dts/arm/renesas/ra/ra4/r7fa4l1bx.dtsi:685 */
			zephyr,memory-region = "OFS_BANKSEL_SEL_MEMORY"; /* in zephyr/dts/arm/renesas/ra/ra4/r7fa4l1bx.dtsi:686 */
			reg = < 0x100a290 0x4 >;                         /* in zephyr/dts/arm/renesas/ra/ra4/r7fa4l1bx.dtsi:687 */
			status = "okay";                                 /* in zephyr/dts/arm/renesas/ra/ra4/r7fa4l1bx.dtsi:688 */
		};

		/* node '/soc/option-setting-bps-sel@100a2c0' defined in zephyr/dts/arm/renesas/ra/ra4/r7fa4l1bx.dtsi:691 */
		option_setting_bps_sel: option-setting-bps-sel@100a2c0 {
			compatible = "zephyr,memory-region";         /* in zephyr/dts/arm/renesas/ra/ra4/r7fa4l1bx.dtsi:692 */
			zephyr,memory-region = "OFS_BPS_SEL_MEMORY"; /* in zephyr/dts/arm/renesas/ra/ra4/r7fa4l1bx.dtsi:693 */
			reg = < 0x100a2c0 0xc >;                     /* in zephyr/dts/arm/renesas/ra/ra4/r7fa4l1bx.dtsi:694 */
			status = "okay";                             /* in zephyr/dts/arm/renesas/ra/ra4/r7fa4l1bx.dtsi:695 */
		};

		/* node '/soc/flash-controller@407e0000' defined in zephyr/dts/arm/renesas/ra/ra4/r7fa4l1bd4cfp.dtsi:11 */
		flash: flash-controller@407e0000 {
			compatible = "renesas,ra-flash-hp-controller"; /* in zephyr/dts/arm/renesas/ra/ra4/r7fa4l1bd4cfp.dtsi:12 */
			reg = < 0x407e0000 0x10000 >;                  /* in zephyr/dts/arm/renesas/ra/ra4/r7fa4l1bd4cfp.dtsi:13 */
			#address-cells = < 0x1 >;                      /* in zephyr/dts/arm/renesas/ra/ra4/r7fa4l1bd4cfp.dtsi:14 */
			#size-cells = < 0x1 >;                         /* in zephyr/dts/arm/renesas/ra/ra4/r7fa4l1bd4cfp.dtsi:15 */
			interrupts = < 0x31 0x1 >,
			             < 0x32 0x1 >;                     /* in zephyr/dts/arm/renesas/ra/ra4/r7fa4l1bd4cfp.dtsi:16 */
			interrupt-names = "frdyi",
			                  "fiferr";                    /* in zephyr/dts/arm/renesas/ra/ra4/r7fa4l1bd4cfp.dtsi:17 */
			flash-hardware-version = < 0x4 >;              /* in zephyr/dts/arm/renesas/ra/ra4/r7fa4l1bd4cfp.dtsi:18 */
			#erase-block-cells = < 0x2 >;                  /* in zephyr/dts/arm/renesas/ra/ra4/r7fa4l1bd4cfp.dtsi:19 */
			phandle = < 0x22 >;                            /* in zephyr/dts/arm/renesas/ra/ra4/r7fa4l1bd4cfp.dtsi:26 */

			/* node '/soc/flash-controller@407e0000/flash@0' defined in zephyr/dts/arm/renesas/ra/ra4/r7fa4l1bd4cfp.dtsi:21 */
			flash0: flash@0 {
				compatible = "renesas,ra-nv-code-flash"; /* in zephyr/dts/arm/renesas/ra/ra4/r7fa4l1bd4cfp.dtsi:22 */
				reg = < 0x0 0x80000 >;                   /* in zephyr/dts/arm/renesas/ra/ra4/r7fa4l1bd4cfp.dtsi:23 */
				write-block-size = < 0x8 >;              /* in zephyr/dts/arm/renesas/ra/ra4/r7fa4l1bd4cfp.dtsi:24 */
				erase-block-size = < 0x800 >;            /* in zephyr/dts/arm/renesas/ra/ra4/r7fa4l1bd4cfp.dtsi:25 */
				erase-blocks = < &flash 0x100 0x800 >;   /* in zephyr/dts/arm/renesas/ra/ra4/r7fa4l1bd4cfp.dtsi:26 */
				programming-enable;                      /* in zephyr/dts/arm/renesas/ra/ra4/r7fa4l1bd4cfp.dtsi:27 */
			};

			/* node '/soc/flash-controller@407e0000/flash@8000000' defined in zephyr/dts/arm/renesas/ra/ra4/r7fa4l1bd4cfp.dtsi:30 */
			flash1: flash@8000000 {
				compatible = "renesas,ra-nv-data-flash"; /* in zephyr/dts/arm/renesas/ra/ra4/r7fa4l1bd4cfp.dtsi:31 */
				reg = < 0x8000000 0x2000 >;              /* in zephyr/dts/arm/renesas/ra/ra4/r7fa4l1bd4cfp.dtsi:32 */
				write-block-size = < 0x1 >;              /* in zephyr/dts/arm/renesas/ra/ra4/r7fa4l1bd4cfp.dtsi:33 */
				erase-block-size = < 0x100 >;            /* in zephyr/dts/arm/renesas/ra/ra4/r7fa4l1bd4cfp.dtsi:34 */
				programming-enable;                      /* in zephyr/dts/arm/renesas/ra/ra4/r7fa4l1bd4cfp.dtsi:35 */

				/* node '/soc/flash-controller@407e0000/flash@8000000/partitions' defined in zephyr/boards/renesas/ek_ra4l1/ek_ra4l1.dts:218 */
				partitions {
					compatible = "fixed-partitions"; /* in zephyr/boards/renesas/ek_ra4l1/ek_ra4l1.dts:219 */
					#address-cells = < 0x1 >;        /* in zephyr/boards/renesas/ek_ra4l1/ek_ra4l1.dts:220 */
					#size-cells = < 0x1 >;           /* in zephyr/boards/renesas/ek_ra4l1/ek_ra4l1.dts:221 */

					/* node '/soc/flash-controller@407e0000/flash@8000000/partitions/partition@0' defined in zephyr/boards/renesas/ek_ra4l1/ek_ra4l1.dts:223 */
					storage_partition: partition@0 {
						label = "storage";    /* in zephyr/boards/renesas/ek_ra4l1/ek_ra4l1.dts:224 */
						reg = < 0x0 0x2000 >; /* in zephyr/boards/renesas/ek_ra4l1/ek_ra4l1.dts:225 */
					};
				};
			};
		};
	};

	/* node '/cpus' defined in zephyr/dts/arm/renesas/ra/ra4/r7fa4l1bx.dtsi:16 */
	cpus {
		#address-cells = < 0x1 >; /* in zephyr/dts/arm/renesas/ra/ra4/r7fa4l1bx.dtsi:17 */
		#size-cells = < 0x0 >;    /* in zephyr/dts/arm/renesas/ra/ra4/r7fa4l1bx.dtsi:18 */

		/* node '/cpus/cpu@0' defined in zephyr/dts/arm/renesas/ra/ra4/r7fa4l1bx.dtsi:20 */
		cpu@0 {
			device_type = "cpu";           /* in zephyr/dts/arm/renesas/ra/ra4/r7fa4l1bx.dtsi:21 */
			compatible = "arm,cortex-m33"; /* in zephyr/dts/arm/renesas/ra/ra4/r7fa4l1bx.dtsi:22 */
			reg = < 0x0 >;                 /* in zephyr/dts/arm/renesas/ra/ra4/r7fa4l1bx.dtsi:23 */
			#address-cells = < 0x1 >;      /* in zephyr/dts/arm/renesas/ra/ra4/r7fa4l1bx.dtsi:24 */
			#size-cells = < 0x1 >;         /* in zephyr/dts/arm/renesas/ra/ra4/r7fa4l1bx.dtsi:25 */

			/* node '/cpus/cpu@0/mpu@e000ed90' defined in zephyr/dts/arm/renesas/ra/ra4/r7fa4l1bx.dtsi:27 */
			mpu: mpu@e000ed90 {
				compatible = "arm,armv8m-mpu"; /* in zephyr/dts/arm/renesas/ra/ra4/r7fa4l1bx.dtsi:28 */
				reg = < 0xe000ed90 0x40 >;     /* in zephyr/dts/arm/renesas/ra/ra4/r7fa4l1bx.dtsi:29 */
			};
		};
	};

	/* node '/clocks' defined in zephyr/dts/arm/renesas/ra/ra4/r7fa4l1bx.dtsi:699 */
	clocks: clocks {
		#address-cells = < 0x1 >; /* in zephyr/dts/arm/renesas/ra/ra4/r7fa4l1bx.dtsi:700 */
		#size-cells = < 0x1 >;    /* in zephyr/dts/arm/renesas/ra/ra4/r7fa4l1bx.dtsi:701 */

		/* node '/clocks/clock-main-osc' defined in zephyr/dts/arm/renesas/ra/ra4/r7fa4l1bx.dtsi:703 */
		xtal: clock-main-osc {
			compatible = "renesas,ra-cgc-external-clock"; /* in zephyr/dts/arm/renesas/ra/ra4/r7fa4l1bx.dtsi:704 */
			clock-frequency = < 0x7a1200 >;               /* in zephyr/boards/renesas/ek_ra4l1/ek_ra4l1.dts:84 */
			mosel = < 0x0 >;                              /* in zephyr/boards/renesas/ek_ra4l1/ek_ra4l1.dts:85 */
			#clock-cells = < 0x0 >;                       /* in zephyr/boards/renesas/ek_ra4l1/ek_ra4l1.dts:86 */
			status = "okay";                              /* in zephyr/boards/renesas/ek_ra4l1/ek_ra4l1.dts:87 */
			phandle = < 0x23 >;                           /* in zephyr/boards/renesas/ek_ra4l1/ek_ra4l1.dts:95 */
		};

		/* node '/clocks/clock-hoco' defined in zephyr/dts/arm/renesas/ra/ra4/r7fa4l1bx.dtsi:710 */
		hoco: clock-hoco {
			compatible = "fixed-clock";      /* in zephyr/dts/arm/renesas/ra/ra4/r7fa4l1bx.dtsi:711 */
			clock-frequency = < 0x2dc6c00 >; /* in zephyr/dts/arm/renesas/ra/ra4/r7fa4l1bx.dtsi:712 */
			#clock-cells = < 0x0 >;          /* in zephyr/dts/arm/renesas/ra/ra4/r7fa4l1bx.dtsi:713 */
		};

		/* node '/clocks/clock-loco' defined in zephyr/dts/arm/renesas/ra/ra4/r7fa4l1bx.dtsi:716 */
		loco: clock-loco {
			compatible = "fixed-clock";   /* in zephyr/dts/arm/renesas/ra/ra4/r7fa4l1bx.dtsi:717 */
			clock-frequency = < 0x8000 >; /* in zephyr/dts/arm/renesas/ra/ra4/r7fa4l1bx.dtsi:718 */
			#clock-cells = < 0x0 >;       /* in zephyr/dts/arm/renesas/ra/ra4/r7fa4l1bx.dtsi:719 */
		};

		/* node '/clocks/clock-moco' defined in zephyr/dts/arm/renesas/ra/ra4/r7fa4l1bx.dtsi:722 */
		moco: clock-moco {
			compatible = "fixed-clock";     /* in zephyr/dts/arm/renesas/ra/ra4/r7fa4l1bx.dtsi:723 */
			clock-frequency = < 0x7a1200 >; /* in zephyr/dts/arm/renesas/ra/ra4/r7fa4l1bx.dtsi:724 */
			#clock-cells = < 0x0 >;         /* in zephyr/dts/arm/renesas/ra/ra4/r7fa4l1bx.dtsi:725 */
		};

		/* node '/clocks/clock-subclk' defined in zephyr/dts/arm/renesas/ra/ra4/r7fa4l1bx.dtsi:728 */
		subclk: clock-subclk {
			compatible = "renesas,ra-cgc-subclk"; /* in zephyr/dts/arm/renesas/ra/ra4/r7fa4l1bx.dtsi:729 */
			clock-frequency = < 0x8000 >;         /* in zephyr/dts/arm/renesas/ra/ra4/r7fa4l1bx.dtsi:730 */
			#clock-cells = < 0x0 >;               /* in zephyr/dts/arm/renesas/ra/ra4/r7fa4l1bx.dtsi:731 */
			status = "okay";                      /* in zephyr/boards/renesas/ek_ra4l1/ek_ra4l1.dts:91 */
			phandle = < 0x21 >;                   /* in zephyr/dts/arm/renesas/ra/ra4/r7fa4l1bx.dtsi:630 */
		};

		/* node '/clocks/pll' defined in zephyr/dts/arm/renesas/ra/ra4/r7fa4l1bx.dtsi:735 */
		pll: pll {
			compatible = "renesas,ra-cgc-pll"; /* in zephyr/dts/arm/renesas/ra/ra4/r7fa4l1bx.dtsi:736 */
			#clock-cells = < 0x0 >;            /* in zephyr/dts/arm/renesas/ra/ra4/r7fa4l1bx.dtsi:737 */
			clocks = < &xtal >;                /* in zephyr/boards/renesas/ek_ra4l1/ek_ra4l1.dts:95 */
			div = < 0x1 >;                     /* in zephyr/boards/renesas/ek_ra4l1/ek_ra4l1.dts:96 */
			mul = < 0xa 0x0 >;                 /* in zephyr/boards/renesas/ek_ra4l1/ek_ra4l1.dts:97 */
			status = "okay";                   /* in zephyr/boards/renesas/ek_ra4l1/ek_ra4l1.dts:98 */
			phandle = < 0x24 >;                /* in zephyr/dts/arm/renesas/ra/ra4/r7fa4l1bx.dtsi:753 */
		};

		/* node '/clocks/pclkblock@40084000' defined in zephyr/dts/arm/renesas/ra/ra4/r7fa4l1bx.dtsi:746 */
		pclkblock: pclkblock@40084000 {
			compatible = "renesas,ra-cgc-pclk-block"; /* in zephyr/dts/arm/renesas/ra/ra4/r7fa4l1bx.dtsi:747 */
			reg = < 0x40084000 0x4 >,
			      < 0x40084004 0x4 >,
			      < 0x40084008 0x4 >,
			      < 0x4008400c 0x4 >,
			      < 0x40084010 0x4 >;                 /* in zephyr/dts/arm/renesas/ra/ra4/r7fa4l1bx.dtsi:748 */
			reg-names = "MSTPA",
			            "MSTPB",
			            "MSTPC",
			            "MSTPD",
			            "MSTPE";                      /* in zephyr/dts/arm/renesas/ra/ra4/r7fa4l1bx.dtsi:750 */
			#clock-cells = < 0x0 >;                   /* in zephyr/dts/arm/renesas/ra/ra4/r7fa4l1bx.dtsi:752 */
			clocks = < &pll >;                        /* in zephyr/dts/arm/renesas/ra/ra4/r7fa4l1bx.dtsi:753 */
			status = "okay";                          /* in zephyr/dts/arm/renesas/ra/ra4/r7fa4l1bx.dtsi:754 */

			/* node '/clocks/pclkblock@40084000/iclk' defined in zephyr/dts/arm/renesas/ra/ra4/r7fa4l1bx.dtsi:756 */
			iclk: iclk {
				compatible = "renesas,ra-cgc-pclk"; /* in zephyr/dts/arm/renesas/ra/ra4/r7fa4l1bx.dtsi:757 */
				clock-frequency = < 0x4c4b400 >;    /* in zephyr/dts/arm/renesas/ra/ra4/r7fa4l1bx.dtsi:758 */
				div = < 0x1 >;                      /* in zephyr/dts/arm/renesas/ra/ra4/r7fa4l1bx.dtsi:759 */
				#clock-cells = < 0x2 >;             /* in zephyr/dts/arm/renesas/ra/ra4/r7fa4l1bx.dtsi:760 */
				status = "okay";                    /* in zephyr/dts/arm/renesas/ra/ra4/r7fa4l1bx.dtsi:761 */
				phandle = < 0x13 >;                 /* in zephyr/dts/arm/renesas/ra/ra4/r7fa4l1bx.dtsi:150 */
			};

			/* node '/clocks/pclkblock@40084000/pclka' defined in zephyr/dts/arm/renesas/ra/ra4/r7fa4l1bx.dtsi:764 */
			pclka: pclka {
				compatible = "renesas,ra-cgc-pclk"; /* in zephyr/dts/arm/renesas/ra/ra4/r7fa4l1bx.dtsi:765 */
				div = < 0x1 >;                      /* in zephyr/dts/arm/renesas/ra/ra4/r7fa4l1bx.dtsi:766 */
				#clock-cells = < 0x2 >;             /* in zephyr/dts/arm/renesas/ra/ra4/r7fa4l1bx.dtsi:767 */
				status = "okay";                    /* in zephyr/dts/arm/renesas/ra/ra4/r7fa4l1bx.dtsi:768 */
				phandle = < 0x14 >;                 /* in zephyr/dts/arm/renesas/ra/ra4/r7fa4l1bx.dtsi:165 */
			};

			/* node '/clocks/pclkblock@40084000/pclkb' defined in zephyr/dts/arm/renesas/ra/ra4/r7fa4l1bx.dtsi:771 */
			pclkb: pclkb {
				compatible = "renesas,ra-cgc-pclk"; /* in zephyr/dts/arm/renesas/ra/ra4/r7fa4l1bx.dtsi:772 */
				div = < 0x2 >;                      /* in zephyr/dts/arm/renesas/ra/ra4/r7fa4l1bx.dtsi:773 */
				#clock-cells = < 0x2 >;             /* in zephyr/dts/arm/renesas/ra/ra4/r7fa4l1bx.dtsi:774 */
				status = "okay";                    /* in zephyr/dts/arm/renesas/ra/ra4/r7fa4l1bx.dtsi:775 */
				phandle = < 0x2 >;                  /* in zephyr/dts/arm/renesas/ra/ra4/r7fa4l1bx.dtsi:47 */
			};

			/* node '/clocks/pclkblock@40084000/pclkc' defined in zephyr/dts/arm/renesas/ra/ra4/r7fa4l1bx.dtsi:778 */
			pclkc: pclkc {
				compatible = "renesas,ra-cgc-pclk"; /* in zephyr/dts/arm/renesas/ra/ra4/r7fa4l1bx.dtsi:779 */
				div = < 0x2 >;                      /* in zephyr/dts/arm/renesas/ra/ra4/r7fa4l1bx.dtsi:780 */
				#clock-cells = < 0x2 >;             /* in zephyr/dts/arm/renesas/ra/ra4/r7fa4l1bx.dtsi:781 */
				status = "okay";                    /* in zephyr/dts/arm/renesas/ra/ra4/r7fa4l1bx.dtsi:782 */
			};

			/* node '/clocks/pclkblock@40084000/pclkd' defined in zephyr/dts/arm/renesas/ra/ra4/r7fa4l1bx.dtsi:785 */
			pclkd: pclkd {
				compatible = "renesas,ra-cgc-pclk"; /* in zephyr/dts/arm/renesas/ra/ra4/r7fa4l1bx.dtsi:786 */
				div = < 0x1 >;                      /* in zephyr/dts/arm/renesas/ra/ra4/r7fa4l1bx.dtsi:787 */
				#clock-cells = < 0x2 >;             /* in zephyr/dts/arm/renesas/ra/ra4/r7fa4l1bx.dtsi:788 */
				status = "okay";                    /* in zephyr/dts/arm/renesas/ra/ra4/r7fa4l1bx.dtsi:789 */
				phandle = < 0x1c >;                 /* in zephyr/dts/arm/renesas/ra/ra4/r7fa4l1bx.dtsi:358 */
			};

			/* node '/clocks/pclkblock@40084000/fclk' defined in zephyr/dts/arm/renesas/ra/ra4/r7fa4l1bx.dtsi:792 */
			fclk: fclk {
				compatible = "renesas,ra-cgc-pclk"; /* in zephyr/dts/arm/renesas/ra/ra4/r7fa4l1bx.dtsi:793 */
				div = < 0x2 >;                      /* in zephyr/dts/arm/renesas/ra/ra4/r7fa4l1bx.dtsi:794 */
				#clock-cells = < 0x2 >;             /* in zephyr/dts/arm/renesas/ra/ra4/r7fa4l1bx.dtsi:795 */
				status = "okay";                    /* in zephyr/dts/arm/renesas/ra/ra4/r7fa4l1bx.dtsi:796 */
			};

			/* node '/clocks/pclkblock@40084000/clkout' defined in zephyr/dts/arm/renesas/ra/ra4/r7fa4l1bx.dtsi:799 */
			clkout: clkout {
				compatible = "renesas,ra-cgc-pclk"; /* in zephyr/dts/arm/renesas/ra/ra4/r7fa4l1bx.dtsi:800 */
				#clock-cells = < 0x2 >;             /* in zephyr/dts/arm/renesas/ra/ra4/r7fa4l1bx.dtsi:801 */
				status = "disabled";                /* in zephyr/dts/arm/renesas/ra/ra4/r7fa4l1bx.dtsi:802 */
			};

			/* node '/clocks/pclkblock@40084000/uclk' defined in zephyr/dts/arm/renesas/ra/ra4/r7fa4l1bx.dtsi:805 */
			uclk: uclk {
				compatible = "renesas,ra-cgc-pclk"; /* in zephyr/dts/arm/renesas/ra/ra4/r7fa4l1bx.dtsi:806 */
				#clock-cells = < 0x2 >;             /* in zephyr/dts/arm/renesas/ra/ra4/r7fa4l1bx.dtsi:807 */
				status = "disabled";                /* in zephyr/dts/arm/renesas/ra/ra4/r7fa4l1bx.dtsi:808 */
			};

			/* node '/clocks/pclkblock@40084000/canfdclk' defined in zephyr/dts/arm/renesas/ra/ra4/r7fa4l1bx.dtsi:811 */
			canfdclk: canfdclk {
				compatible = "renesas,ra-cgc-pclk"; /* in zephyr/dts/arm/renesas/ra/ra4/r7fa4l1bx.dtsi:812 */
				#clock-cells = < 0x2 >;             /* in zephyr/dts/arm/renesas/ra/ra4/r7fa4l1bx.dtsi:813 */
				clocks = < &pll >;                  /* in zephyr/boards/renesas/ek_ra4l1/ek_ra4l1.dts:102 */
				div = < 0x2 >;                      /* in zephyr/boards/renesas/ek_ra4l1/ek_ra4l1.dts:103 */
				status = "okay";                    /* in zephyr/boards/renesas/ek_ra4l1/ek_ra4l1.dts:104 */
				phandle = < 0x1e >;                 /* in zephyr/dts/arm/renesas/ra/ra4/r7fa4l1bx.dtsi:428 */
			};

			/* node '/clocks/pclkblock@40084000/i3cclk' defined in zephyr/dts/arm/renesas/ra/ra4/r7fa4l1bx.dtsi:817 */
			i3cclk: i3cclk {
				compatible = "renesas,ra-cgc-pclk"; /* in zephyr/dts/arm/renesas/ra/ra4/r7fa4l1bx.dtsi:818 */
				#clock-cells = < 0x2 >;             /* in zephyr/dts/arm/renesas/ra/ra4/r7fa4l1bx.dtsi:819 */
				clocks = < &pll >;                  /* in zephyr/boards/renesas/ek_ra4l1/ek_ra4l1.dts:108 */
				div = < 0x1 >;                      /* in zephyr/boards/renesas/ek_ra4l1/ek_ra4l1.dts:109 */
				status = "okay";                    /* in zephyr/boards/renesas/ek_ra4l1/ek_ra4l1.dts:110 */
				phandle = < 0x17 >;                 /* in zephyr/dts/arm/renesas/ra/ra4/r7fa4l1bx.dtsi:309 */
			};

			/* node '/clocks/pclkblock@40084000/uarta0' defined in zephyr/dts/arm/renesas/ra/ra4/r7fa4l1bx.dtsi:823 */
			uarta0: uarta0 {
				compatible = "renesas,ra-cgc-pclk"; /* in zephyr/dts/arm/renesas/ra/ra4/r7fa4l1bx.dtsi:824 */
				#clock-cells = < 0x2 >;             /* in zephyr/dts/arm/renesas/ra/ra4/r7fa4l1bx.dtsi:825 */
				status = "disabled";                /* in zephyr/dts/arm/renesas/ra/ra4/r7fa4l1bx.dtsi:826 */
			};

			/* node '/clocks/pclkblock@40084000/uarta1' defined in zephyr/dts/arm/renesas/ra/ra4/r7fa4l1bx.dtsi:829 */
			uarta1: uarta1 {
				compatible = "renesas,ra-cgc-pclk"; /* in zephyr/dts/arm/renesas/ra/ra4/r7fa4l1bx.dtsi:830 */
				#clock-cells = < 0x2 >;             /* in zephyr/dts/arm/renesas/ra/ra4/r7fa4l1bx.dtsi:831 */
				status = "disabled";                /* in zephyr/dts/arm/renesas/ra/ra4/r7fa4l1bx.dtsi:832 */
			};
		};
	};

	/* node '/leds' defined in zephyr/boards/renesas/ek_ra4l1/ek_ra4l1.dts:28 */
	leds {
		compatible = "gpio-leds"; /* in zephyr/boards/renesas/ek_ra4l1/ek_ra4l1.dts:29 */

		/* node '/leds/led1' defined in zephyr/boards/renesas/ek_ra4l1/ek_ra4l1.dts:31 */
		led1: led1 {
			gpios = < &ioport6 0x9 0x0 >; /* in zephyr/boards/renesas/ek_ra4l1/ek_ra4l1.dts:32 */
			label = "LED1";               /* in zephyr/boards/renesas/ek_ra4l1/ek_ra4l1.dts:33 */
		};

		/* node '/leds/led2' defined in zephyr/boards/renesas/ek_ra4l1/ek_ra4l1.dts:36 */
		led2: led2 {
			gpios = < &ioport6 0xa 0x0 >; /* in zephyr/boards/renesas/ek_ra4l1/ek_ra4l1.dts:37 */
			label = "LED2";               /* in zephyr/boards/renesas/ek_ra4l1/ek_ra4l1.dts:38 */
		};

		/* node '/leds/led3' defined in zephyr/boards/renesas/ek_ra4l1/ek_ra4l1.dts:41 */
		led3: led3 {
			gpios = < &ioport6 0x1 0x0 >; /* in zephyr/boards/renesas/ek_ra4l1/ek_ra4l1.dts:42 */
			label = "LED3";               /* in zephyr/boards/renesas/ek_ra4l1/ek_ra4l1.dts:43 */
		};
	};

	/* node '/buttons' defined in zephyr/boards/renesas/ek_ra4l1/ek_ra4l1.dts:47 */
	buttons {
		compatible = "gpio-keys"; /* in zephyr/boards/renesas/ek_ra4l1/ek_ra4l1.dts:48 */

		/* node '/buttons/s1' defined in zephyr/boards/renesas/ek_ra4l1/ek_ra4l1.dts:50 */
		button0: s1 {
			gpios = < &ioport0 0x0 0x11 >;  /* in zephyr/boards/renesas/ek_ra4l1/ek_ra4l1.dts:51 */
			label = "Push button switch 1"; /* in zephyr/boards/renesas/ek_ra4l1/ek_ra4l1.dts:52 */
			zephyr,code = < 0xb >;          /* in zephyr/boards/renesas/ek_ra4l1/ek_ra4l1.dts:53 */
		};

		/* node '/buttons/s2' defined in zephyr/boards/renesas/ek_ra4l1/ek_ra4l1.dts:56 */
		button1: s2 {
			gpios = < &ioport0 0x1 0x11 >;  /* in zephyr/boards/renesas/ek_ra4l1/ek_ra4l1.dts:57 */
			label = "Push button switch 2"; /* in zephyr/boards/renesas/ek_ra4l1/ek_ra4l1.dts:58 */
			zephyr,code = < 0x2 >;          /* in zephyr/boards/renesas/ek_ra4l1/ek_ra4l1.dts:59 */
		};
	};

	/* node '/can-phy0' defined in zephyr/boards/renesas/ek_ra4l1/ek_ra4l1.dts:70 */
	transceiver0: can-phy0 {
		compatible = "microchip,mcp2562fd",
		             "can-transceiver-gpio";  /* in zephyr/boards/renesas/ek_ra4l1/ek_ra4l1.dts:71 */
		standby-gpios = < &ioport1 0x6 0x1 >; /* in zephyr/boards/renesas/ek_ra4l1/ek_ra4l1.dts:72 */
		max-bitrate = < 0x4c4b40 >;           /* in zephyr/boards/renesas/ek_ra4l1/ek_ra4l1.dts:73 */
		#phy-cells = < 0x0 >;                 /* in zephyr/boards/renesas/ek_ra4l1/ek_ra4l1.dts:74 */
		phandle = < 0x20 >;                   /* in zephyr/boards/renesas/ek_ra4l1/ek_ra4l1.dts:207 */
	};

	/* node '/zephyr,user' defined in zephyr/boards/renesas/ek_ra4l1/ek_ra4l1.dts:77 */
	zephyr,user {
		i3c-pullup-gpios = < &ioport5 0x8 0x1 >,
		                   < &ioport5 0x9 0x1 >; /* in zephyr/boards/renesas/ek_ra4l1/ek_ra4l1.dts:78 */
	};
};
